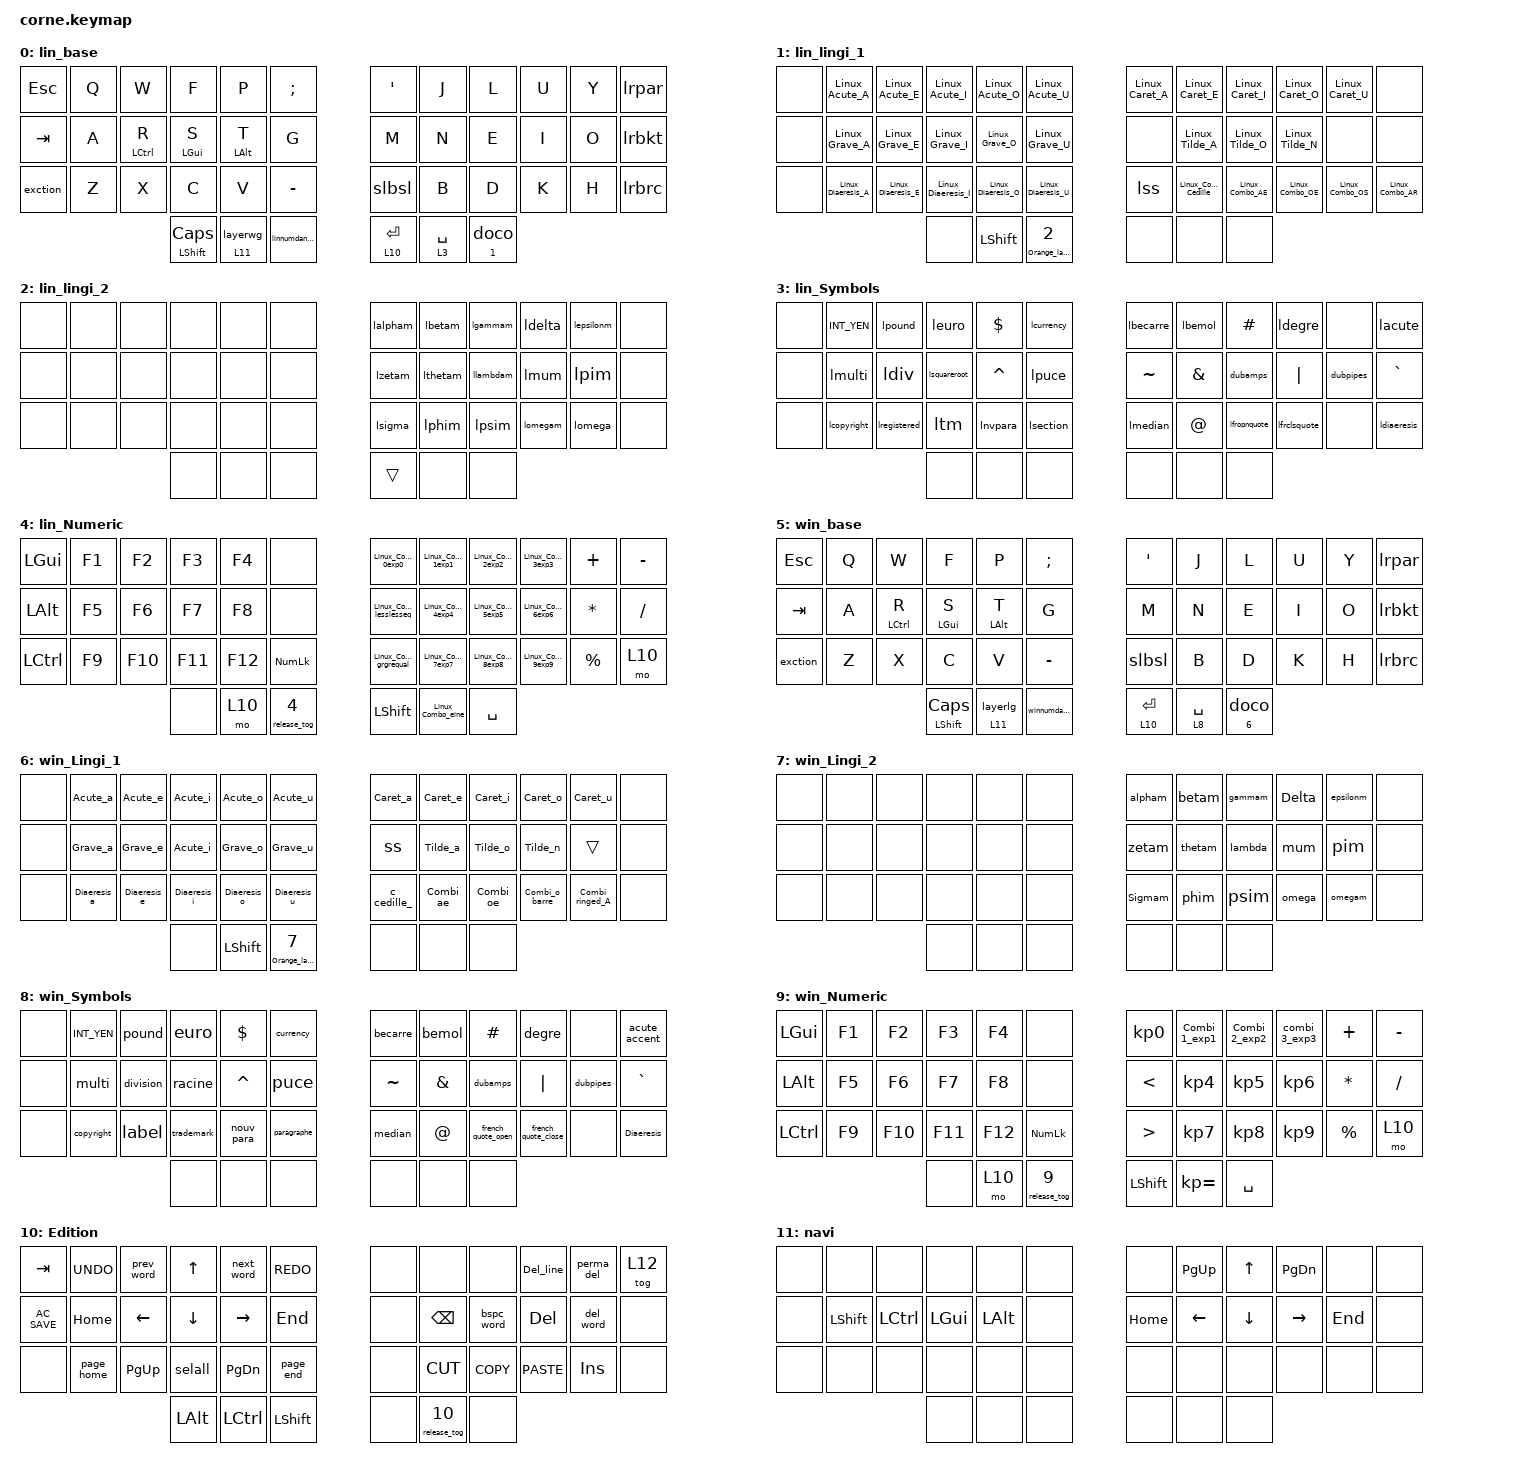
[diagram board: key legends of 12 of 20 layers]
#include <behaviors.dtsi>
#include <dt-bindings/zmk/bt.h>
#include <dt-bindings/zmk/keys.h>
#include <dt-bindings/zmk/rgb.h>

#define BASE 0
#define GAMING 1
#define LINGI 2
#define LINGI2 3
#define SYMBOLS 4
#define NUM 5
#define GAMINGNUM 6
#define EDITION 7
#define NAVI 8
#define APPLAUNCH 9
#define MEDIADISP 10
#define WINDOWMAN 11
#define CC 12
#define KC 13
#define LOCKED 14

#define MO_TOG(layer) &mo_tog layer layer

&sk { quick-release; };

/ {
    behaviors {
        exction: exction {
            compatible = "zmk,behavior-mod-morph";
            label = "EXCTION";
            bindings = <&kp EXCL>, <&kp QUESTION>;

            #binding-cells = <0>;
            mods = <(MOD_LSFT)>;
        };

        lrpar: lrpar {
            compatible = "zmk,behavior-mod-morph";
            label = "LRPAR";
            bindings = <&kp LPAR>, <&kp RPAR>;

            #binding-cells = <0>;
            mods = <(MOD_LSFT)>;
        };

        lrbkt: lrbkt {
            compatible = "zmk,behavior-mod-morph";
            label = "LRBKT";
            bindings = <&kp LBKT>, <&kp RBKT>;

            #binding-cells = <0>;
            mods = <(MOD_LSFT)>;
        };

        lrbrc: lrbrc {
            compatible = "zmk,behavior-mod-morph";
            label = "LRBRC";
            bindings = <&kp LBRC>, <&kp RBRC>;

            #binding-cells = <0>;
            mods = <(MOD_LSFT)>;
        };

        doco: doco {
            compatible = "zmk,behavior-mod-morph";
            label = "DOCO";
            bindings = <&kp DOT>, <&kp COMMA>;

            #binding-cells = <0>;
            mods = <(MOD_LSFT)>;
        };

        slbsl: slbsl {
            compatible = "zmk,behavior-mod-morph";
            label = "SLBSL";
            bindings = <&kp SLASH>, <&kp BACKSLASH>;

            #binding-cells = <0>;
            mods = <(MOD_LSFT)>;
        };

        homerow: homerow {
            compatible = "zmk,behavior-hold-tap";
            label = "HOMEROW";
            bindings = <&sk>, <&kp>;

            #binding-cells = <2>;
            hold-trigger-key-positions = <15 14 13>;
            tapping-term-ms = <200>;
            flavor = "tap-preferred";
        };

        htkp: htkp {
            compatible = "zmk,behavior-hold-tap";
            label = "HTKP";
            bindings = <&kp>, <&kp>;

            #binding-cells = <2>;
            tapping-term-ms = <200>;
        };

        orangelayer: orangelayer {
            compatible = "zmk,behavior-hold-tap";
            label = "ORANGELAYER";
            bindings = <&moorange>, <&doco>;

            #binding-cells = <2>;
            hold-trigger-key-positions = <39 40 41>;
            tapping-term-ms = <100>;
        };

        cyanlayer: cyanlayer {
            compatible = "zmk,behavior-hold-tap";
            label = "CYANLAYER";
            bindings = <&mocyan>, <&kp>;

            #binding-cells = <2>;
            hold-trigger-key-positions = <39 40 41>;
            tapping-term-ms = <100>;
        };

        c_cedille_: c_cedille_ {
            compatible = "zmk,behavior-mod-morph";
            label = "C_CEDILLE_";
            bindings = <&c_cedillem>, <&C_cedille>;

            #binding-cells = <0>;
            mods = <(MOD_LSFT)>;
        };

        Acute_a: Acute_a {
            compatible = "zmk,behavior-mod-morph";
            label = "ACUTE_A";
            bindings = <&aam>, <&Aa>;

            #binding-cells = <0>;
            mods = <(MOD_LSFT)>;
        };

        Acute_e: Acute_e {
            compatible = "zmk,behavior-mod-morph";
            label = "ACUTE_E";
            bindings = <&eam>, <&Ea>;

            #binding-cells = <0>;
            mods = <(MOD_LSFT)>;
        };

        Acute_i: Acute_i {
            compatible = "zmk,behavior-mod-morph";
            label = "ACUTE_I";
            bindings = <&iam>, <&Ia>;

            #binding-cells = <0>;
            mods = <(MOD_LSFT)>;
        };

        Acute_o: Acute_o {
            compatible = "zmk,behavior-mod-morph";
            label = "ACUTE_O";
            bindings = <&oam>, <&Oa>;

            #binding-cells = <0>;
            mods = <(MOD_LSFT)>;
        };

        Acute_u: Acute_u {
            compatible = "zmk,behavior-mod-morph";
            label = "ACUTE_U";
            bindings = <&uam>, <&Ua>;

            #binding-cells = <0>;
            mods = <(MOD_LSFT)>;
        };

        Grave_a: Grave_a {
            compatible = "zmk,behavior-mod-morph";
            label = "GRAVE_A";
            bindings = <&agm>, <&ag>;

            #binding-cells = <0>;
            mods = <(MOD_LSFT)>;
        };

        Grave_e: Grave_e {
            compatible = "zmk,behavior-mod-morph";
            label = "GRAVE_E";
            bindings = <&egm>, <&eg>;

            #binding-cells = <0>;
            mods = <(MOD_LSFT)>;
        };

        Grave_o: Grave_o {
            compatible = "zmk,behavior-mod-morph";
            label = "GRAVE_O";
            bindings = <&ogm>, <&og>;

            #binding-cells = <0>;
            mods = <(MOD_LSFT)>;
        };

        Grave_u: Grave_u {
            compatible = "zmk,behavior-mod-morph";
            label = "GRAVE_U";
            bindings = <&ugm>, <&ug>;

            #binding-cells = <0>;
            mods = <(MOD_LSFT)>;
        };

        Diaeresis_a: Diaeresis_a {
            compatible = "zmk,behavior-mod-morph";
            label = "DIAERESIS_A";
            bindings = <&adm>, <&ad>;

            #binding-cells = <0>;
            mods = <(MOD_LSFT)>;
        };

        Diaeresis_e: Diaeresis_e {
            compatible = "zmk,behavior-mod-morph";
            label = "DIAERESIS_E";
            bindings = <&edm>, <&ed>;

            #binding-cells = <0>;
            mods = <(MOD_LSFT)>;
        };

        Diaeresis_i: Diaeresis_i {
            compatible = "zmk,behavior-mod-morph";
            label = "DIAERESIS_I";
            bindings = <&idm>, <&id>;

            #binding-cells = <0>;
            mods = <(MOD_LSFT)>;
        };

        Diaeresis_o: Diaeresis_o {
            compatible = "zmk,behavior-mod-morph";
            label = "DIAERESIS_O";
            bindings = <&odm>, <&od>;

            #binding-cells = <0>;
            mods = <(MOD_LSFT)>;
        };

        Diaeresis_u: Diaeresis_u {
            compatible = "zmk,behavior-mod-morph";
            label = "DIAERESIS_U";
            bindings = <&udm>, <&ud>;

            #binding-cells = <0>;
            mods = <(MOD_LSFT)>;
        };

        Caret_a: Caret_a {
            compatible = "zmk,behavior-mod-morph";
            label = "CARET_A";
            bindings = <&acm>, <&ac>;

            #binding-cells = <0>;
            mods = <(MOD_LSFT)>;
        };

        Caret_e: Caret_e {
            compatible = "zmk,behavior-mod-morph";
            label = "CARET_E";
            bindings = <&ecm>, <&ec>;

            #binding-cells = <0>;
            mods = <(MOD_LSFT)>;
        };

        Caret_i: Caret_i {
            compatible = "zmk,behavior-mod-morph";
            label = "CARET_I";
            bindings = <&icm>, <&ic>;

            #binding-cells = <0>;
            mods = <(MOD_LSFT)>;
        };

        Caret_o: Caret_o {
            compatible = "zmk,behavior-mod-morph";
            label = "CARET_O";
            bindings = <&ocm>, <&oc>;

            #binding-cells = <0>;
            mods = <(MOD_LSFT)>;
        };

        Caret_u: Caret_u {
            compatible = "zmk,behavior-mod-morph";
            label = "CARET_U";
            bindings = <&ucm>, <&uc>;

            #binding-cells = <0>;
            mods = <(MOD_LSFT)>;
        };

        Tilde_a: Tilde_a {
            compatible = "zmk,behavior-mod-morph";
            label = "TILDE_A";
            bindings = <&atm>, <&at>;

            #binding-cells = <0>;
            mods = <(MOD_LSFT)>;
        };

        Tilde_o: Tilde_o {
            compatible = "zmk,behavior-mod-morph";
            label = "TILDE_O";
            bindings = <&otm>, <&ot>;

            #binding-cells = <0>;
            mods = <(MOD_LSFT)>;
        };

        Tilde_n: Tilde_n {
            compatible = "zmk,behavior-mod-morph";
            label = "TILDE_N";
            bindings = <&ntm>, <&nt>;

            #binding-cells = <0>;
            mods = <(MOD_LSFT)>;
        };

        Combi_ae: Combi_ae {
            compatible = "zmk,behavior-mod-morph";
            label = "COMBI_AE";
            bindings = <&aem>, <&AE>;

            #binding-cells = <0>;
            mods = <(MOD_LSFT)>;
        };

        Combi_oe: Combi_oe {
            compatible = "zmk,behavior-mod-morph";
            label = "COMBI_OE";
            bindings = <&oem>, <&OE>;

            #binding-cells = <0>;
            mods = <(MOD_LSFT)>;
        };

        Combi_o_barre: Combi_o_barre {
            compatible = "zmk,behavior-mod-morph";
            label = "COMBI_O_BARRE";
            bindings = <&o_barrem>, <&O_barre>;

            #binding-cells = <0>;
            mods = <(MOD_LSFT)>;
        };

        Combi_ringed_A: Combi_ringed_A {
            compatible = "zmk,behavior-mod-morph";
            label = "COMBI_RINGED_A";
            bindings = <&arm>, <&Ar>;

            #binding-cells = <0>;
            mods = <(MOD_LSFT)>;
        };

        Combi_1_exp1: Combi_1_exp1 {
            compatible = "zmk,behavior-mod-morph";
            label = "COMBI_1_EXP1";
            bindings = <&kp KP_N1>, <&exp1>;

            #binding-cells = <0>;
            mods = <(MOD_LSFT)>;
        };

        Combi_2_exp2: Combi_2_exp2 {
            compatible = "zmk,behavior-mod-morph";
            label = "COMBI_2_EXP2";
            bindings = <&kp KP_N2>, <&exp2>;

            #binding-cells = <0>;
            mods = <(MOD_LSFT)>;
        };

        combi_3_exp3: combi_3_exp3 {
            compatible = "zmk,behavior-mod-morph";
            label = "COMBI_3_EXP3";
            bindings = <&kp KP_N3>, <&exp3>;

            #binding-cells = <0>;
            mods = <(MOD_LSFT)>;
        };

        Linux_Acute_A: Linux_Acute_A {
            compatible = "zmk,behavior-mod-morph";
            label = "LINUX_ACUTE_A";
            bindings = <&laam>, <&laa>;

            #binding-cells = <0>;
            mods = <(MOD_LSFT)>;
        };

        Linux_Acute_E: Linux_Acute_E {
            compatible = "zmk,behavior-mod-morph";
            label = "LINUX_ACUTE_E";
            bindings = <&leam>, <&lea>;

            #binding-cells = <0>;
            mods = <(MOD_LSFT)>;
        };

        Linux_Acute_I: Linux_Acute_I {
            compatible = "zmk,behavior-mod-morph";
            label = "LINUX_ACUTE_I";
            bindings = <&liam>, <&lia>;

            #binding-cells = <0>;
            mods = <(MOD_LSFT)>;
        };

        Linux_Acute_O: Linux_Acute_O {
            compatible = "zmk,behavior-mod-morph";
            label = "LINUX_ACUTE_O";
            bindings = <&loam>, <&loa>;

            #binding-cells = <0>;
            mods = <(MOD_LSFT)>;
        };

        Linux_Acute_U: Linux_Acute_U {
            compatible = "zmk,behavior-mod-morph";
            label = "LINUX_ACUTE_U";
            bindings = <&luam>, <&lua>;

            #binding-cells = <0>;
            mods = <(MOD_LSFT)>;
        };

        Linux_Grave_A: Linux_Grave_A {
            compatible = "zmk,behavior-mod-morph";
            label = "LINUX_GRAVE_A";
            bindings = <&lagm>, <&lag>;

            #binding-cells = <0>;
            mods = <(MOD_LSFT)>;
        };

        Linux_Grave_E: Linux_Grave_E {
            compatible = "zmk,behavior-mod-morph";
            label = "LINUX_GRAVE_E";
            bindings = <&legm>, <&leg>;

            #binding-cells = <0>;
            mods = <(MOD_LSFT)>;
        };

        Linux_Grave_I: Linux_Grave_I {
            compatible = "zmk,behavior-mod-morph";
            label = "LINUX_GRAVE_I";
            bindings = <&ligm>, <&lig>;

            #binding-cells = <0>;
            mods = <(MOD_LSFT)>;
        };

        Linux_Grave_O: Linux_Grave_O {
            compatible = "zmk,behavior-mod-morph";
            label = "LINUX_GRAVE_O";
            bindings = <&logm>, <&log>;

            #binding-cells = <0>;
            mods = <(MOD_LSFT)>;
        };

        Linux_Grave_U: Linux_Grave_U {
            compatible = "zmk,behavior-mod-morph";
            label = "LINUX_GRAVE_U";
            bindings = <&lugm>, <&lug>;

            #binding-cells = <0>;
            mods = <(MOD_LSFT)>;
        };

        Linux_Diaeresis_A: Linux_Diaeresis_A {
            compatible = "zmk,behavior-mod-morph";
            label = "LINUX_DIAERESIS_A";
            bindings = <&ladm>, <&lad>;

            #binding-cells = <0>;
            mods = <(MOD_LSFT)>;
        };

        Linux_Diaeresis_E: Linux_Diaeresis_E {
            compatible = "zmk,behavior-mod-morph";
            label = "LINUX_DIAERESIS_E";
            bindings = <&ledm>, <&led>;

            #binding-cells = <0>;
            mods = <(MOD_LSFT)>;
        };

        Linux_Diaeresis_I: Linux_Diaeresis_I {
            compatible = "zmk,behavior-mod-morph";
            label = "LINUX_DIAERESIS_I";
            bindings = <&lidm>, <&lid>;

            #binding-cells = <0>;
            mods = <(MOD_LSFT)>;
        };

        Linux_Diaeresis_O: Linux_Diaeresis_O {
            compatible = "zmk,behavior-mod-morph";
            label = "LINUX_DIAERESIS_O";
            bindings = <&lodm>, <&lod>;

            #binding-cells = <0>;
            mods = <(MOD_LSFT)>;
        };

        Linux_Diaeresis_U: Linux_Diaeresis_U {
            compatible = "zmk,behavior-mod-morph";
            label = "LINUX_DIAERESIS_U";
            bindings = <&ludm>, <&lud>;

            #binding-cells = <0>;
            mods = <(MOD_LSFT)>;
        };

        Linux_Caret_A: Linux_Caret_A {
            compatible = "zmk,behavior-mod-morph";
            label = "LINUX_CARET_A";
            bindings = <&lacm>, <&lac>;

            #binding-cells = <0>;
            mods = <(MOD_LSFT)>;
        };

        Linux_Caret_E: Linux_Caret_E {
            compatible = "zmk,behavior-mod-morph";
            label = "LINUX_CARET_E";
            bindings = <&lecm>, <&lec>;

            #binding-cells = <0>;
            mods = <(MOD_LSFT)>;
        };

        Linux_Caret_I: Linux_Caret_I {
            compatible = "zmk,behavior-mod-morph";
            label = "LINUX_CARET_I";
            bindings = <&licm>, <&lic>;

            #binding-cells = <0>;
            mods = <(MOD_LSFT)>;
        };

        Linux_Caret_O: Linux_Caret_O {
            compatible = "zmk,behavior-mod-morph";
            label = "LINUX_CARET_O";
            bindings = <&locm>, <&loc>;

            #binding-cells = <0>;
            mods = <(MOD_LSFT)>;
        };

        Linux_Caret_U: Linux_Caret_U {
            compatible = "zmk,behavior-mod-morph";
            label = "LINUX_CARET_U";
            bindings = <&lucm>, <&luc>;

            #binding-cells = <0>;
            mods = <(MOD_LSFT)>;
        };

        Linux_Tilde_A: Linux_Tilde_A {
            compatible = "zmk,behavior-mod-morph";
            label = "LINUX_TILDE_A";
            bindings = <&latm>, <&lat>;

            #binding-cells = <0>;
            mods = <(MOD_LSFT)>;
        };

        Linux_Tilde_O: Linux_Tilde_O {
            compatible = "zmk,behavior-mod-morph";
            label = "LINUX_TILDE_O";
            bindings = <&lotm>, <&lot>;

            #binding-cells = <0>;
            mods = <(MOD_LSFT)>;
        };

        Linux_Tilde_N: Linux_Tilde_N {
            compatible = "zmk,behavior-mod-morph";
            label = "LINUX_TILDE_N";
            bindings = <&lntm>, <&lnt>;

            #binding-cells = <0>;
            mods = <(MOD_LSFT)>;
        };

        Linux_Combo_AE: Linux_Combo_AE {
            compatible = "zmk,behavior-mod-morph";
            label = "LINUX_COMBO_AE";
            bindings = <&laem>, <&lae>;

            #binding-cells = <0>;
            mods = <(MOD_LSFT)>;
        };

        Linux_Combo_OE: Linux_Combo_OE {
            compatible = "zmk,behavior-mod-morph";
            label = "LINUX_COMBO_OE";
            bindings = <&loem>, <&loe>;

            #binding-cells = <0>;
            mods = <(MOD_LSFT)>;
        };

        Linux_Combo_Cedille: Linux_Combo_Cedille {
            compatible = "zmk,behavior-mod-morph";
            label = "LINUX_COMBO_CEDILLE";
            bindings = <&lcedillem>, <&lcedille>;

            #binding-cells = <0>;
            mods = <(MOD_LSFT)>;
        };

        Linux_Combo_AR: Linux_Combo_AR {
            compatible = "zmk,behavior-mod-morph";
            label = "LINUX_COMBO_AR";
            bindings = <&larm>, <&lar>;

            #binding-cells = <0>;
            mods = <(MOD_LSFT)>;
        };

        Linux_Combo_OS: Linux_Combo_OS {
            compatible = "zmk,behavior-mod-morph";
            label = "LINUX_COMBO_OS";
            bindings = <&losm>, <&los>;

            #binding-cells = <0>;
            mods = <(MOD_LSFT)>;
        };

        Linux_Combo_0exp0: Linux_Combo_0exp0 {
            compatible = "zmk,behavior-mod-morph";
            label = "LINUX_COMBO_0EXP0";
            bindings = <&kp KP_N0>, <&lexp0>;

            #binding-cells = <0>;
            mods = <(MOD_LSFT)>;
        };

        Linux_Combo_1exp1: Linux_Combo_1exp1 {
            compatible = "zmk,behavior-mod-morph";
            label = "LINUX_COMBO_1EXP1";
            bindings = <&kp KP_NUMBER_1>, <&lexp1>;

            #binding-cells = <0>;
            mods = <(MOD_LSFT)>;
        };

        Linux_Combo_2exp2: Linux_Combo_2exp2 {
            compatible = "zmk,behavior-mod-morph";
            label = "LINUX_COMBO_2EXP2";
            bindings = <&kp KP_NUMBER_2>, <&lexp2>;

            #binding-cells = <0>;
            mods = <(MOD_LSFT)>;
        };

        Linux_Combo_3exp3: Linux_Combo_3exp3 {
            compatible = "zmk,behavior-mod-morph";
            label = "LINUX_COMBO_3EXP3";
            bindings = <&kp KP_NUMBER_3>, <&lexp3>;

            #binding-cells = <0>;
            mods = <(MOD_LSFT)>;
        };

        Linux_Combo_4exp4: Linux_Combo_4exp4 {
            compatible = "zmk,behavior-mod-morph";
            label = "LINUX_COMBO_4EXP4";
            bindings = <&kp KP_NUMBER_4>, <&lexp4>;

            #binding-cells = <0>;
            mods = <(MOD_LSFT)>;
        };

        Linux_Combo_5exp5: Linux_Combo_5exp5 {
            compatible = "zmk,behavior-mod-morph";
            label = "LINUX_COMBO_5EXP5";
            bindings = <&kp KP_NUMBER_5>, <&lexp5>;

            #binding-cells = <0>;
            mods = <(MOD_LSFT)>;
        };

        Linux_Combo_6exp6: Linux_Combo_6exp6 {
            compatible = "zmk,behavior-mod-morph";
            label = "LINUX_COMBO_6EXP6";
            bindings = <&kp KP_NUMBER_6>, <&lexp6>;

            #binding-cells = <0>;
            mods = <(MOD_LSFT)>;
        };

        Linux_Combo_7exp7: Linux_Combo_7exp7 {
            compatible = "zmk,behavior-mod-morph";
            label = "LINUX_COMBO_7EXP7";
            bindings = <&kp N7>, <&lexp7>;

            #binding-cells = <0>;
            mods = <(MOD_LSFT)>;
        };

        Linux_Combo_8exp8: Linux_Combo_8exp8 {
            compatible = "zmk,behavior-mod-morph";
            label = "LINUX_COMBO_8EXP8";
            bindings = <&kp N8>, <&lexp8>;

            #binding-cells = <0>;
            mods = <(MOD_LSFT)>;
        };

        Linux_Combo_9exp9: Linux_Combo_9exp9 {
            compatible = "zmk,behavior-mod-morph";
            label = "LINUX_COMBO_9EXP9";
            bindings = <&kp N9>, <&lexp9>;

            #binding-cells = <0>;
            mods = <(MOD_LSFT)>;
        };

        Linux_Combo_lesslesseq: Linux_Combo_lesslesseq {
            compatible = "zmk,behavior-mod-morph";
            label = "LINUX_COMBO_LESSLESSEQ";
            bindings = <&kp LESS_THAN>, <&llessequal>;

            #binding-cells = <0>;
            mods = <(MOD_LSFT)>;
        };

        Linux_Combo_grgrequal: Linux_Combo_grgrequal {
            compatible = "zmk,behavior-mod-morph";
            label = "LINUX_COMBO_GRGREQUAL";
            bindings = <&kp GREATER_THAN>, <&lgreaterequal>;

            #binding-cells = <0>;
            mods = <(MOD_LSFT)>;
        };

        Linux_Combo_eine: Linux_Combo_eine {
            compatible = "zmk,behavior-mod-morph";
            label = "LINUX_COMBO_EINE";
            bindings = <&kp EQUAL>, <&linequal>;

            #binding-cells = <0>;
            mods = <(MOD_LSFT)>;
        };

        layerwg: layerwg {
            compatible = "zmk,behavior-mod-morph";
            label = "LAYERWG";
            bindings = <&to 5>, <&tog 13>;

            #binding-cells = <0>;
            mods = <(MOD_LCTL)>;
        };

        mo_kp: mo_kp {
            compatible = "zmk,behavior-hold-tap";
            label = "MO_KP";
            bindings = <&mo>, <&kp>;

            #binding-cells = <2>;
            hold-trigger-key-positions = <39 40 41 38 37>;
            tapping-term-ms = <130>;
        };

        layerlg: layerlg {
            compatible = "zmk,behavior-mod-morph";
            label = "LAYERLG";
            bindings = <&to 0>, <&tog 13>;

            #binding-cells = <0>;
            mods = <(MOD_LCTL)>;
        };

        wgnavi: wgnavi {
            compatible = "zmk,behavior-hold-tap";
            label = "WGNAVI";
            bindings = <&mo>, <&layerwg>;

            #binding-cells = <2>;
            hold-trigger-key-positions = <39 40 41 38 37>;
            tapping-term-ms = <130>;
        };

        lgnavi: lgnavi {
            compatible = "zmk,behavior-hold-tap";
            label = "LGNAVI";
            bindings = <&mo>, <&layerlg>;

            #binding-cells = <2>;
            hold-trigger-key-positions = <39 40 41 38 37>;
            tapping-term-ms = <130>;
        };

        linnumdance: linnumdance {
            compatible = "zmk,behavior-tap-dance";
            label = "LINNUMDANCE";
            #binding-cells = <0>;
            bindings = <&mo 4>, <&tog 4>;
        };

        winnumdance: winnumdance {
            compatible = "zmk,behavior-tap-dance";
            label = "WINNUMDANCE";
            #binding-cells = <0>;
            bindings = <&mo 9>, <&tog 9>;
        };
    };

    macros {
        mogreen: morgb {
            compatible = "zmk,behavior-macro-one-param";
            #binding-cells = <1>;
            bindings =
                <&macro_param_1to1>,
                <&macro_press>,
                <&mo MACRO_PLACEHOLDER>,
                <&macro_tap>,
                <&rgb_ug RGB_COLOR_HSB(123,100,49)>,
                <&macro_pause_for_release>,
                <&macro_param_1to1>,
                <&macro_release>,
                <&mo MACRO_PLACEHOLDER>,
                <&macro_tap>,
                <&rgb_ug RGB_COLOR_HSB(301,100,48)>;

            label = "MORGB";
        };

        moorange: moorange {
            compatible = "zmk,behavior-macro-one-param";
            #binding-cells = <1>;
            bindings =
                <&macro_param_1to1>,
                <&macro_press>,
                <&mo MACRO_PLACEHOLDER>,
                <&macro_tap>,
                <&rgb_ug RGB_COLOR_HSB(24,100,49)>,
                <&macro_press>,
                <&macro_pause_for_release>,
                <&macro_release>,
                <&macro_param_1to1 &mo MACRO_PLACEHOLDER>,
                <&macro_tap>,
                <&rgb_ug RGB_COLOR_HSB(301,100,48)>;

            label = "MOORANGE";
        };

        mocyan: mocyan {
            compatible = "zmk,behavior-macro-one-param";
            #binding-cells = <1>;
            bindings =
                <&macro_param_1to1>,
                <&macro_press>,
                <&mo MACRO_PLACEHOLDER>,
                <&macro_tap>,
                <&rgb_ug RGB_COLOR_HSB(180,100,49)>,
                <&macro_pause_for_release>,
                <&macro_release>,
                <&macro_param_1to1 &mo MACRO_PLACEHOLDER>,
                <&macro_tap>,
                <&rgb_ug RGB_COLOR_HSB(301,100,48)>;

            label = "MOCYAN";
        };

        release_tog: release_tog {
            compatible = "zmk,behavior-macro-one-param";
            #binding-cells = <1>;
            bindings =
                <&macro_param_1to1>,
                <&macro_tap>,
                <&tog MACRO_PLACEHOLDER>,
                <&macro_tap>,
                <&rgb_ug RGB_COLOR_HSB(301,100,48)>;

            label = "RELEASE_TOG";
        };

        tog_purple: tog_purple {
            compatible = "zmk,behavior-macro-one-param";
            #binding-cells = <1>;
            bindings =
                <&macro_tap>,
                <&rgb_ug RGB_COLOR_HSB(267,100,49) &macro_param_1to1>,
                <&macro_tap>,
                <&tog MACRO_PLACEHOLDER>;

            label = "TOG_PURPLE";
        };

        tog_yellow: tog_yellow {
            compatible = "zmk,behavior-macro-one-param";
            #binding-cells = <1>;
            bindings =
                <&macro_tap>,
                <&rgb_ug RGB_COLOR_HSB(56,100,49) &macro_param_1to1>,
                <&macro_tap>,
                <&tog MACRO_PLACEHOLDER>;

            label = "TOG_YELLOW";
        };

        mopurple: mopurple {
            compatible = "zmk,behavior-macro-one-param";
            #binding-cells = <1>;
            bindings =
                <&macro_param_1to1>,
                <&macro_press>,
                <&mo MACRO_PLACEHOLDER>,
                <&macro_tap>,
                <&rgb_ug RGB_COLOR_HSB(267,100,49)>,
                <&macro_pause_for_release>,
                <&macro_param_1to1>,
                <&macro_release>,
                <&kp MACRO_PLACEHOLDER>,
                <&macro_tap>,
                <&rgb_ug RGB_COLOR_HSB(304,100,50)>;

            label = "MOPURPLE";
        };

        moyellow: yellow {
            compatible = "zmk,behavior-macro-one-param";
            #binding-cells = <1>;
            bindings =
                <&macro_param_1to1>,
                <&macro_press>,
                <&mo MACRO_PLACEHOLDER>,
                <&macro_tap>,
                <&rgb_ug RGB_COLOR_HSB(63,100,49)>,
                <&macro_pause_for_release>,
                <&macro_param_1to1>,
                <&macro_release>,
                <&mo MACRO_PLACEHOLDER>,
                <&macro_tap>,
                <&rgb_ug RGB_COLOR_HSB(304,100,50)>;

            label = "YELLOW";
        };

        aem: aem {
            compatible = "zmk,behavior-macro";
            #binding-cells = <0>;
            bindings =
                <&macro_press>,
                <&kp LALT>,
                <&macro_tap>,
                <&kp KP_NUMBER_0 &kp KP_NUMBER_2 &kp KP_NUMBER_3 &kp KP_NUMBER_0>,
                <&macro_release>,
                <&kp LALT>;

            label = "AEM";
        };

        AE: AE {
            compatible = "zmk,behavior-macro";
            #binding-cells = <0>;
            bindings =
                <&macro_press>,
                <&kp LALT>,
                <&macro_tap>,
                <&kp KP_NUMBER_0 &kp KP_NUMBER_1 &kp KP_NUMBER_9 &kp KP_NUMBER_8>,
                <&macro_release>,
                <&kp LALT>;

            label = "AE";
        };

        c_cedillem: c_cedillem {
            compatible = "zmk,behavior-macro";
            #binding-cells = <0>;
            bindings =
                <&macro_press>,
                <&kp LALT>,
                <&macro_tap>,
                <&kp KP_NUMBER_0 &kp KP_NUMBER_2 &kp KP_NUMBER_3 &kp KP_NUMBER_1>,
                <&macro_release>,
                <&kp LALT>;

            label = "C_CEDILLEM";
        };

        C_cedille: C_cedille {
            compatible = "zmk,behavior-macro";
            #binding-cells = <0>;
            bindings =
                <&macro_press>,
                <&kp LALT>,
                <&macro_tap>,
                <&kp KP_NUMBER_0 &kp KP_NUMBER_1 &kp KP_NUMBER_9 &kp KP_NUMBER_9>,
                <&macro_release>,
                <&kp LALT>;

            label = "C_CEDILLE";
        };

        o_barrem: o_barrem {
            compatible = "zmk,behavior-macro";
            #binding-cells = <0>;
            bindings =
                <&macro_press>,
                <&kp LALT>,
                <&macro_tap>,
                <&kp KP_NUMBER_0 &kp KP_NUMBER_2 &kp KP_NUMBER_4 &kp KP_NUMBER_8>,
                <&macro_release>,
                <&kp LALT>;

            label = "O_BARREM";
        };

        O_barre: O_barre {
            compatible = "zmk,behavior-macro";
            #binding-cells = <0>;
            bindings =
                <&macro_press>,
                <&kp LALT>,
                <&macro_tap>,
                <&kp KP_NUMBER_0 &kp KP_NUMBER_2 &kp KP_NUMBER_1 &kp KP_NUMBER_6>,
                <&macro_release>,
                <&kp LALT>;

            label = "O_BARRE";
        };

        ss: ss {
            compatible = "zmk,behavior-macro";
            #binding-cells = <0>;
            bindings =
                <&macro_press>,
                <&kp LALT>,
                <&macro_tap>,
                <&kp KP_NUMBER_0 &kp KP_NUMBER_2 &kp KP_NUMBER_2 &kp KP_NUMBER_3>,
                <&macro_release>,
                <&kp LALT>;

            label = "SS";
        };

        oem: oem {
            compatible = "zmk,behavior-macro";
            #binding-cells = <0>;
            bindings =
                <&macro_press>,
                <&kp LALT>,
                <&macro_tap>,
                <&kp KP_NUMBER_0 &kp KP_NUMBER_1 &kp KP_NUMBER_5 &kp KP_NUMBER_6>,
                <&macro_release>,
                <&kp LALT>;

            label = "OEM";
        };

        OE: OE {
            compatible = "zmk,behavior-macro";
            #binding-cells = <0>;
            bindings =
                <&macro_press>,
                <&kp LALT>,
                <&macro_tap>,
                <&kp KP_NUMBER_0 &kp KP_NUMBER_1 &kp KP_NUMBER_4 &kp KP_NUMBER_0>,
                <&macro_release>,
                <&kp LALT>;

            label = "OE";
        };

        arm: arm {
            compatible = "zmk,behavior-macro";
            #binding-cells = <0>;
            bindings =
                <&macro_press>,
                <&kp LALT>,
                <&macro_tap>,
                <&kp KP_NUMBER_0 &kp KP_NUMBER_2 &kp KP_NUMBER_2 &kp KP_NUMBER_9>,
                <&macro_release>,
                <&kp LALT>;

            label = "ARM";
        };

        Ar: Ar {
            compatible = "zmk,behavior-macro";
            #binding-cells = <0>;
            bindings =
                <&macro_press>,
                <&kp LALT>,
                <&macro_tap>,
                <&kp KP_NUMBER_0 &kp KP_NUMBER_1 &kp KP_NUMBER_9 &kp KP_NUMBER_7>,
                <&macro_release>,
                <&kp LALT>;

            label = "AR";
        };

        Aa: aa {
            compatible = "zmk,behavior-macro";
            #binding-cells = <0>;
            bindings =
                <&macro_press>,
                <&kp LALT>,
                <&macro_tap>,
                <&kp KP_NUMBER_0 &kp KP_NUMBER_1 &kp KP_NUMBER_9 &kp KP_NUMBER_3>,
                <&macro_release>,
                <&kp LALT>;

            label = "AA";
        };

        aam: aam {
            compatible = "zmk,behavior-macro";
            #binding-cells = <0>;
            bindings =
                <&macro_press>,
                <&kp LALT>,
                <&macro_tap>,
                <&kp KP_NUMBER_0 &kp KP_NUMBER_2 &kp KP_NUMBER_2 &kp KP_NUMBER_5>,
                <&macro_release>,
                <&kp LALT>;

            label = "AAM";
        };

        Ea: Ea {
            compatible = "zmk,behavior-macro";
            #binding-cells = <0>;
            bindings =
                <&macro_press>,
                <&kp LALT>,
                <&macro_tap>,
                <&kp KP_NUMBER_0 &kp KP_NUMBER_2 &kp KP_NUMBER_0 &kp KP_NUMBER_1>,
                <&macro_release>,
                <&kp LALT>;

            label = "EA";
        };

        eam: eam {
            compatible = "zmk,behavior-macro";
            #binding-cells = <0>;
            bindings =
                <&macro_press>,
                <&kp LALT>,
                <&macro_tap>,
                <&kp KP_NUMBER_0 &kp KP_NUMBER_2 &kp KP_NUMBER_3 &kp KP_NUMBER_3>,
                <&macro_release>,
                <&kp LALT>;

            label = "EAM";
        };

        Ia: Ia {
            compatible = "zmk,behavior-macro";
            #binding-cells = <0>;
            bindings =
                <&macro_press>,
                <&kp LALT>,
                <&macro_tap>,
                <&kp KP_NUMBER_0 &kp KP_NUMBER_2 &kp KP_NUMBER_0 &kp KP_NUMBER_5>,
                <&macro_release>,
                <&kp LALT>;

            label = "IA";
        };

        iam: iam {
            compatible = "zmk,behavior-macro";
            #binding-cells = <0>;
            bindings =
                <&macro_press>,
                <&kp LALT>,
                <&macro_tap>,
                <&kp KP_NUMBER_0 &kp KP_NUMBER_2 &kp KP_NUMBER_3 &kp KP_NUMBER_7>,
                <&macro_release>,
                <&kp LALT>;

            label = "IAM";
        };

        Oa: Oa {
            compatible = "zmk,behavior-macro";
            #binding-cells = <0>;
            bindings =
                <&macro_press>,
                <&kp LALT>,
                <&macro_tap>,
                <&kp KP_NUMBER_0 &kp KP_NUMBER_2 &kp KP_NUMBER_1 &kp KP_NUMBER_1>,
                <&macro_release>,
                <&kp LALT>;

            label = "OA";
        };

        oam: oam {
            compatible = "zmk,behavior-macro";
            #binding-cells = <0>;
            bindings =
                <&macro_press>,
                <&kp LALT>,
                <&macro_tap>,
                <&kp KP_NUMBER_0 &kp KP_NUMBER_2 &kp KP_NUMBER_4 &kp KP_NUMBER_3>,
                <&macro_release>,
                <&kp LALT>;

            label = "OAM";
        };

        Ua: Ua {
            compatible = "zmk,behavior-macro";
            #binding-cells = <0>;
            bindings =
                <&macro_press>,
                <&kp LALT>,
                <&macro_tap>,
                <&kp KP_NUMBER_0 &kp KP_NUMBER_2 &kp KP_NUMBER_1 &kp KP_NUMBER_8>,
                <&macro_release>,
                <&kp LALT>;

            label = "UA";
        };

        uam: uam {
            compatible = "zmk,behavior-macro";
            #binding-cells = <0>;
            bindings =
                <&macro_press>,
                <&kp LALT>,
                <&macro_tap>,
                <&kp KP_NUMBER_0 &kp KP_NUMBER_2 &kp KP_NUMBER_5 &kp KP_NUMBER_0>,
                <&macro_release>,
                <&kp LALT>;

            label = "UAM";
        };

        ag: ag {
            compatible = "zmk,behavior-macro";
            #binding-cells = <0>;
            bindings =
                <&macro_press>,
                <&kp LALT>,
                <&macro_tap>,
                <&kp KP_NUMBER_0 &kp KP_NUMBER_1 &kp KP_NUMBER_9 &kp KP_NUMBER_2>,
                <&macro_release>,
                <&kp LALT>;

            label = "AG";
        };

        agm: agm {
            compatible = "zmk,behavior-macro";
            #binding-cells = <0>;
            bindings =
                <&macro_press>,
                <&kp LALT>,
                <&macro_tap>,
                <&kp KP_NUMBER_0 &kp KP_NUMBER_2 &kp KP_NUMBER_2 &kp KP_NUMBER_4>,
                <&macro_release>,
                <&kp LALT>;

            label = "AGM";
        };

        eg: eg {
            compatible = "zmk,behavior-macro";
            #binding-cells = <0>;
            bindings =
                <&macro_press>,
                <&kp LALT>,
                <&macro_tap>,
                <&kp KP_NUMBER_0 &kp KP_NUMBER_2 &kp KP_NUMBER_0 &kp KP_NUMBER_0>,
                <&macro_release>,
                <&kp LALT>;

            label = "EG";
        };

        egm: egm {
            compatible = "zmk,behavior-macro";
            #binding-cells = <0>;
            bindings =
                <&macro_press>,
                <&kp LALT>,
                <&macro_tap>,
                <&kp KP_NUMBER_0 &kp KP_NUMBER_2 &kp KP_NUMBER_3 &kp KP_N2>,
                <&macro_release>,
                <&kp LALT>;

            label = "EGM";
        };

        ug: ug {
            compatible = "zmk,behavior-macro";
            #binding-cells = <0>;
            bindings =
                <&macro_press>,
                <&kp LALT>,
                <&macro_tap>,
                <&kp KP_NUMBER_0 &kp KP_NUMBER_2 &kp KP_NUMBER_1 &kp KP_NUMBER_7>,
                <&macro_release>,
                <&kp LALT>;

            label = "UG";
        };

        ugm: ugm {
            compatible = "zmk,behavior-macro";
            #binding-cells = <0>;
            bindings =
                <&macro_press>,
                <&kp LALT>,
                <&macro_tap>,
                <&kp KP_NUMBER_0 &kp KP_NUMBER_2 &kp KP_NUMBER_4 &kp KP_NUMBER_9>,
                <&macro_release>,
                <&kp LALT>;

            label = "UGM";
        };

        og: og {
            compatible = "zmk,behavior-macro";
            #binding-cells = <0>;
            bindings =
                <&macro_press>,
                <&kp LALT>,
                <&macro_tap>,
                <&kp KP_NUMBER_0 &kp KP_NUMBER_2 &kp KP_NUMBER_1 &kp KP_NUMBER_0>,
                <&macro_release>,
                <&kp LALT>;

            label = "OG";
        };

        ogm: ogm {
            compatible = "zmk,behavior-macro";
            #binding-cells = <0>;
            bindings =
                <&macro_press>,
                <&kp LALT>,
                <&macro_tap>,
                <&kp KP_NUMBER_0 &kp KP_NUMBER_2 &kp KP_NUMBER_4 &kp KP_NUMBER_2>,
                <&macro_release>,
                <&kp LALT>;

            label = "OGM";
        };

        adm: adm {
            compatible = "zmk,behavior-macro";
            #binding-cells = <0>;
            bindings =
                <&macro_press>,
                <&kp LALT>,
                <&macro_tap>,
                <&kp KP_NUMBER_0 &kp KP_NUMBER_2 &kp KP_NUMBER_2 &kp KP_NUMBER_8>,
                <&macro_release>,
                <&kp LALT>;

            label = "ADM";
        };

        edm: edm {
            compatible = "zmk,behavior-macro";
            #binding-cells = <0>;
            bindings =
                <&macro_press>,
                <&kp LALT>,
                <&macro_tap>,
                <&kp KP_NUMBER_0 &kp KP_NUMBER_2 &kp KP_NUMBER_3 &kp KP_NUMBER_5>,
                <&macro_release>,
                <&kp LALT>;

            label = "EDM";
        };

        idm: idm {
            compatible = "zmk,behavior-macro";
            #binding-cells = <0>;
            bindings =
                <&macro_press>,
                <&kp LALT>,
                <&macro_tap>,
                <&kp KP_NUMBER_0 &kp KP_NUMBER_2 &kp KP_NUMBER_3 &kp KP_NUMBER_9>,
                <&macro_release>,
                <&kp LALT>;

            label = "IDM";
        };

        odm: odm {
            compatible = "zmk,behavior-macro";
            #binding-cells = <0>;
            bindings =
                <&macro_press>,
                <&kp LALT>,
                <&macro_tap>,
                <&kp KP_NUMBER_0 &kp KP_NUMBER_2 &kp KP_NUMBER_4 &kp KP_NUMBER_6>,
                <&macro_release>,
                <&kp LALT>;

            label = "ODM";
        };

        udm: udm {
            compatible = "zmk,behavior-macro";
            #binding-cells = <0>;
            bindings =
                <&macro_press>,
                <&kp LALT>,
                <&macro_tap>,
                <&kp KP_NUMBER_0 &kp KP_NUMBER_2 &kp KP_NUMBER_5 &kp KP_NUMBER_2>,
                <&macro_release>,
                <&kp LALT>;

            label = "UDM";
        };

        ad: ad {
            compatible = "zmk,behavior-macro";
            #binding-cells = <0>;
            bindings =
                <&macro_press>,
                <&kp LALT>,
                <&macro_tap>,
                <&kp KP_NUMBER_0 &kp KP_NUMBER_1 &kp KP_NUMBER_9 &kp KP_NUMBER_6>,
                <&macro_release>,
                <&kp LALT>;

            label = "AD";
        };

        ed: ed {
            compatible = "zmk,behavior-macro";
            #binding-cells = <0>;
            bindings =
                <&macro_press>,
                <&kp LALT>,
                <&macro_tap>,
                <&kp KP_NUMBER_0 &kp KP_NUMBER_2 &kp KP_NUMBER_0 &kp KP_NUMBER_3>,
                <&macro_release>,
                <&kp LALT>;

            label = "ED";
        };

        id: id {
            compatible = "zmk,behavior-macro";
            #binding-cells = <0>;
            bindings =
                <&macro_press>,
                <&kp LALT>,
                <&macro_tap>,
                <&kp KP_NUMBER_0 &kp KP_NUMBER_2 &kp KP_NUMBER_0 &kp KP_NUMBER_7>,
                <&macro_release>,
                <&kp LALT>;

            label = "ID";
        };

        od: od {
            compatible = "zmk,behavior-macro";
            #binding-cells = <0>;
            bindings =
                <&macro_press>,
                <&kp LALT>,
                <&macro_tap>,
                <&kp KP_NUMBER_0 &kp KP_NUMBER_2 &kp KP_NUMBER_1 &kp KP_NUMBER_4>,
                <&macro_release>,
                <&kp LALT>;

            label = "OD";
        };

        ud: ud {
            compatible = "zmk,behavior-macro";
            #binding-cells = <0>;
            bindings =
                <&macro_press>,
                <&kp LALT>,
                <&macro_tap>,
                <&kp KP_NUMBER_0 &kp KP_NUMBER_2 &kp KP_NUMBER_2 &kp KP_NUMBER_0>,
                <&macro_release>,
                <&kp LALT>;

            label = "UD";
        };

        ac: ac {
            compatible = "zmk,behavior-macro";
            #binding-cells = <0>;
            bindings =
                <&macro_press>,
                <&kp LALT>,
                <&macro_tap>,
                <&kp KP_NUMBER_0 &kp KP_NUMBER_1 &kp KP_NUMBER_9 &kp KP_NUMBER_4>,
                <&macro_release>,
                <&kp LALT>;

            label = "AC";
        };

        ec: ec {
            compatible = "zmk,behavior-macro";
            #binding-cells = <0>;
            bindings =
                <&macro_press>,
                <&kp LALT>,
                <&macro_tap>,
                <&kp KP_NUMBER_0 &kp KP_NUMBER_2 &kp KP_NUMBER_0 &kp KP_NUMBER_2>,
                <&macro_release>,
                <&kp LALT>;

            label = "EC";
        };

        ic: ic {
            compatible = "zmk,behavior-macro";
            #binding-cells = <0>;
            bindings =
                <&macro_press>,
                <&kp LALT>,
                <&macro_tap>,
                <&kp KP_NUMBER_0 &kp KP_NUMBER_2 &kp KP_NUMBER_0 &kp KP_NUMBER_6>,
                <&macro_release>,
                <&kp LALT>;

            label = "IC";
        };

        oc: oc {
            compatible = "zmk,behavior-macro";
            #binding-cells = <0>;
            bindings =
                <&macro_press>,
                <&kp LALT>,
                <&macro_tap>,
                <&kp KP_NUMBER_0 &kp KP_NUMBER_2 &kp KP_NUMBER_1 &kp KP_NUMBER_2>,
                <&macro_release>,
                <&kp LALT>;

            label = "OC";
        };

        uc: uc {
            compatible = "zmk,behavior-macro";
            #binding-cells = <0>;
            bindings =
                <&macro_press>,
                <&kp LALT>,
                <&macro_tap>,
                <&kp KP_NUMBER_0 &kp KP_NUMBER_2 &kp KP_NUMBER_1 &kp KP_NUMBER_9>,
                <&macro_release>,
                <&kp LALT>;

            label = "UC";
        };

        acm: acm {
            compatible = "zmk,behavior-macro";
            #binding-cells = <0>;
            bindings =
                <&macro_press>,
                <&kp LALT>,
                <&macro_tap>,
                <&kp KP_NUMBER_0 &kp KP_NUMBER_2 &kp KP_NUMBER_2 &kp KP_NUMBER_6>,
                <&macro_release>,
                <&kp LALT>;

            label = "ACM";
        };

        ecm: ecm {
            compatible = "zmk,behavior-macro";
            #binding-cells = <0>;
            bindings =
                <&macro_press>,
                <&kp LALT>,
                <&macro_tap>,
                <&kp KP_NUMBER_0 &kp KP_NUMBER_2 &kp KP_NUMBER_3 &kp KP_NUMBER_4>,
                <&macro_release>,
                <&kp LALT>;

            label = "ECM";
        };

        icm: icm {
            compatible = "zmk,behavior-macro";
            #binding-cells = <0>;
            bindings =
                <&macro_press>,
                <&kp LALT>,
                <&macro_tap>,
                <&kp KP_NUMBER_0 &kp KP_NUMBER_2 &kp KP_NUMBER_3 &kp KP_NUMBER_8>,
                <&macro_release>,
                <&kp LALT>;

            label = "ICM";
        };

        ocm: ocm {
            compatible = "zmk,behavior-macro";
            #binding-cells = <0>;
            bindings =
                <&macro_press>,
                <&kp LALT>,
                <&macro_tap>,
                <&kp KP_NUMBER_0 &kp KP_NUMBER_2 &kp KP_NUMBER_4 &kp KP_NUMBER_4>,
                <&macro_release>,
                <&kp LALT>;

            label = "OCM";
        };

        ucm: ucm {
            compatible = "zmk,behavior-macro";
            #binding-cells = <0>;
            bindings =
                <&macro_press>,
                <&kp LALT>,
                <&macro_tap>,
                <&kp KP_NUMBER_0 &kp KP_NUMBER_2 &kp KP_NUMBER_5 &kp KP_NUMBER_1>,
                <&macro_release>,
                <&kp LALT>;

            label = "UCM";
        };

        ntm: ntm {
            compatible = "zmk,behavior-macro";
            #binding-cells = <0>;
            bindings =
                <&macro_press>,
                <&kp LALT>,
                <&macro_tap>,
                <&kp KP_NUMBER_0 &kp KP_NUMBER_2 &kp KP_NUMBER_4 &kp KP_NUMBER_1>,
                <&macro_release>,
                <&kp LALT>;

            label = "NTM";
        };

        nt: nt {
            compatible = "zmk,behavior-macro";
            #binding-cells = <0>;
            bindings =
                <&macro_press>,
                <&kp LALT>,
                <&macro_tap>,
                <&kp KP_NUMBER_0 &kp KP_NUMBER_2 &kp KP_NUMBER_0 &kp KP_NUMBER_9>,
                <&macro_release>,
                <&kp LALT>;

            label = "NT";
        };

        atm: atm {
            compatible = "zmk,behavior-macro";
            #binding-cells = <0>;
            bindings =
                <&macro_press>,
                <&kp LALT>,
                <&macro_tap>,
                <&kp KP_NUMBER_0 &kp KP_NUMBER_2 &kp KP_NUMBER_2 &kp KP_NUMBER_7>,
                <&macro_release>,
                <&kp LALT>;

            label = "ATM";
        };

        at: at {
            compatible = "zmk,behavior-macro";
            #binding-cells = <0>;
            bindings =
                <&macro_press>,
                <&kp LALT>,
                <&macro_tap>,
                <&kp KP_NUMBER_0 &kp KP_NUMBER_1 &kp KP_NUMBER_9 &kp KP_NUMBER_5>,
                <&macro_release>,
                <&kp LALT>;

            label = "AT";
        };

        otm: otm {
            compatible = "zmk,behavior-macro";
            #binding-cells = <0>;
            bindings =
                <&macro_press>,
                <&kp LALT>,
                <&macro_tap>,
                <&kp KP_NUMBER_0 &kp KP_NUMBER_2 &kp KP_NUMBER_4 &kp KP_NUMBER_5>,
                <&macro_release>,
                <&kp LALT>;

            label = "OTM";
        };

        ot: ot {
            compatible = "zmk,behavior-macro";
            #binding-cells = <0>;
            bindings =
                <&macro_press>,
                <&kp LALT>,
                <&macro_tap>,
                <&kp KP_NUMBER_0 &kp KP_NUMBER_2 &kp KP_NUMBER_1 &kp KP_NUMBER_3>,
                <&macro_release>,
                <&kp LALT>;

            label = "OT";
        };

        Orange_layer_2: Orange_layer_2 {
            compatible = "zmk,behavior-macro-one-param";
            #binding-cells = <1>;
            bindings =
                <&macro_param_1to1>,
                <&macro_press>,
                <&mo MACRO_PLACEHOLDER>,
                <&macro_press>,
                <&rgb_ug RGB_COLOR_HSB(38,100,70)>,
                <&macro_press>,
                <&macro_pause_for_release>,
                <&macro_release>,
                <&macro_param_1to1 &mo MACRO_PLACEHOLDER>,
                <&macro_tap>,
                <&rgb_ug RGB_COLOR_HSB(301,100,48)>;

            label = "ORANGE_LAYER_2";
        };

        alpham: alpha {
            compatible = "zmk,behavior-macro";
            #binding-cells = <0>;
            bindings =
                <&macro_press>,
                <&kp LALT>,
                <&macro_tap>,
                <&kp KP_NUMBER_0 &kp KP_NUMBER_9 &kp KP_NUMBER_4 &kp KP_NUMBER_5>,
                <&macro_release>,
                <&kp LALT>;

            label = "ALPHA";
        };

        betam: betam {
            compatible = "zmk,behavior-macro";
            #binding-cells = <0>;
            bindings =
                <&macro_press>,
                <&kp LALT>,
                <&macro_tap>,
                <&kp KP_NUMBER_0 &kp KP_NUMBER_9 &kp KP_NUMBER_4 &kp KP_NUMBER_6>,
                <&macro_release>,
                <&kp LALT>;

            label = "BETAM";
        };

        gammam: gammam {
            compatible = "zmk,behavior-macro";
            #binding-cells = <0>;
            bindings =
                <&macro_press>,
                <&kp LALT>,
                <&macro_tap>,
                <&kp KP_NUMBER_0 &kp KP_NUMBER_9 &kp KP_NUMBER_4 &kp KP_NUMBER_7>,
                <&macro_release>,
                <&kp LALT>;

            label = "GAMMAM";
        };

        Delta: Delta {
            compatible = "zmk,behavior-macro";
            #binding-cells = <0>;
            bindings =
                <&macro_press>,
                <&kp LALT>,
                <&macro_tap>,
                <&kp KP_NUMBER_0 &kp KP_NUMBER_9 &kp KP_NUMBER_1 &kp KP_NUMBER_6>,
                <&macro_release>,
                <&kp LALT>;

            label = "DELTA";
        };

        epsilonm: epsilonm {
            compatible = "zmk,behavior-macro";
            #binding-cells = <0>;
            bindings =
                <&macro_press>,
                <&kp LALT>,
                <&macro_tap>,
                <&kp KP_NUMBER_0 &kp KP_NUMBER_9 &kp KP_NUMBER_4 &kp KP_NUMBER_9>,
                <&macro_release>,
                <&kp LALT>;

            label = "EPSILONM";
        };

        zetam: zetam {
            compatible = "zmk,behavior-macro";
            #binding-cells = <0>;
            bindings =
                <&macro_press>,
                <&kp LALT>,
                <&macro_tap>,
                <&kp KP_NUMBER_0 &kp KP_NUMBER_9 &kp KP_NUMBER_5 &kp KP_NUMBER_0>,
                <&macro_release>,
                <&kp LALT>;

            label = "ZETAM";
        };

        thetam: thetam {
            compatible = "zmk,behavior-macro";
            #binding-cells = <0>;
            bindings =
                <&macro_press>,
                <&kp LALT>,
                <&macro_tap>,
                <&kp KP_NUMBER_0 &kp KP_NUMBER_9 &kp KP_NUMBER_5 &kp KP_NUMBER_2>,
                <&macro_release>,
                <&kp LALT>;

            label = "THETAM";
        };

        lambda: lambda {
            compatible = "zmk,behavior-macro";
            #binding-cells = <0>;
            bindings =
                <&macro_press>,
                <&kp LALT>,
                <&macro_tap>,
                <&kp KP_NUMBER_0 &kp KP_NUMBER_9 &kp KP_NUMBER_5 &kp KP_NUMBER_5>,
                <&macro_release>,
                <&kp LALT>;

            label = "LAMBDA";
        };

        mum: mum {
            compatible = "zmk,behavior-macro";
            #binding-cells = <0>;
            bindings =
                <&macro_press>,
                <&kp LALT>,
                <&macro_tap>,
                <&kp KP_NUMBER_0 &kp KP_NUMBER_9 &kp KP_NUMBER_5 &kp KP_NUMBER_6>,
                <&macro_release>,
                <&kp LALT>;

            label = "MUM";
        };

        pim: pim {
            compatible = "zmk,behavior-macro";
            #binding-cells = <0>;
            bindings =
                <&macro_press>,
                <&kp LALT>,
                <&macro_tap>,
                <&kp KP_NUMBER_0 &kp KP_NUMBER_9 &kp KP_NUMBER_6 &kp KP_NUMBER_0>,
                <&macro_release>,
                <&kp LALT>;

            label = "PIM";
        };

        Sigmam: Sigmam {
            compatible = "zmk,behavior-macro";
            #binding-cells = <0>;
            bindings =
                <&macro_press>,
                <&kp LALT>,
                <&macro_tap>,
                <&kp KP_NUMBER_0 &kp KP_NUMBER_9 &kp KP_NUMBER_3 &kp KP_NUMBER_1>,
                <&macro_release>,
                <&kp LALT>;

            label = "SIGMAM";
        };

        phim: phim {
            compatible = "zmk,behavior-macro";
            #binding-cells = <0>;
            bindings =
                <&macro_press>,
                <&kp LALT>,
                <&macro_tap>,
                <&kp KP_NUMBER_0 &kp KP_NUMBER_9 &kp KP_NUMBER_6 &kp KP_NUMBER_6>,
                <&macro_release>,
                <&kp LALT>;

            label = "PHIM";
        };

        psim: psim {
            compatible = "zmk,behavior-macro";
            #binding-cells = <0>;
            bindings =
                <&macro_press>,
                <&kp LALT>,
                <&macro_tap>,
                <&kp KP_NUMBER_0 &kp KP_NUMBER_9 &kp KP_NUMBER_6 &kp KP_NUMBER_8>,
                <&macro_release>,
                <&kp LALT>;

            label = "PSIM";
        };

        omega: omega {
            compatible = "zmk,behavior-macro";
            #binding-cells = <0>;
            bindings =
                <&macro_press>,
                <&kp LALT>,
                <&macro_tap>,
                <&kp KP_NUMBER_0 &kp KP_NUMBER_9 &kp KP_NUMBER_3 &kp KP_NUMBER_7>,
                <&macro_release>,
                <&kp LALT>;

            label = "OMEGA";
        };

        omegam: omegam {
            compatible = "zmk,behavior-macro";
            #binding-cells = <0>;
            bindings =
                <&macro_press>,
                <&kp LALT>,
                <&macro_tap>,
                <&kp KP_NUMBER_0 &kp KP_NUMBER_9 &kp KP_NUMBER_6 &kp KP_NUMBER_9>,
                <&macro_release>,
                <&kp LALT>;

            label = "OMEGAM";
        };

        pound: pound {
            compatible = "zmk,behavior-macro";
            #binding-cells = <0>;
            bindings =
                <&macro_press>,
                <&kp LALT>,
                <&macro_tap>,
                <&kp KP_NUMBER_0 &kp KP_NUMBER_1 &kp KP_NUMBER_6 &kp KP_NUMBER_3>,
                <&macro_release>,
                <&kp LALT>;

            label = "POUND";
        };

        euro: euro {
            compatible = "zmk,behavior-macro";
            #binding-cells = <0>;
            bindings =
                <&macro_press>,
                <&kp LALT>,
                <&macro_tap>,
                <&kp KP_NUMBER_0 &kp KP_NUMBER_1 &kp KP_NUMBER_2 &kp KP_NUMBER_8>,
                <&macro_release>,
                <&kp LALT>;

            label = "EURO";
        };

        currency: currency {
            compatible = "zmk,behavior-macro";
            #binding-cells = <0>;
            bindings =
                <&macro_press>,
                <&kp LALT>,
                <&macro_tap>,
                <&kp KP_NUMBER_0 &kp KP_NUMBER_1 &kp KP_NUMBER_6 &kp KP_NUMBER_4>,
                <&macro_release>,
                <&kp LALT>;

            label = "CURRENCY";
        };

        multi: multi {
            compatible = "zmk,behavior-macro";
            #binding-cells = <0>;
            bindings =
                <&macro_press>,
                <&kp LALT>,
                <&macro_tap>,
                <&kp KP_NUMBER_0 &kp KP_NUMBER_2 &kp KP_NUMBER_1 &kp KP_NUMBER_5>,
                <&macro_release>,
                <&kp LALT>;

            label = "MULTI";
        };

        division: division {
            compatible = "zmk,behavior-macro";
            #binding-cells = <0>;
            bindings =
                <&macro_press>,
                <&kp LALT>,
                <&macro_tap>,
                <&kp KP_NUMBER_0 &kp KP_NUMBER_2 &kp KP_NUMBER_4 &kp KP_NUMBER_7>,
                <&macro_release>,
                <&kp LALT>;

            label = "DIVISION";
        };

        racine: racine {
            compatible = "zmk,behavior-macro";
            #binding-cells = <0>;
            bindings =
                <&macro_press>,
                <&kp LALT>,
                <&macro_tap>,
                <&kp KP_NUMBER_0 &kp KP_NUMBER_2 &kp KP_NUMBER_5 &kp KP_NUMBER_1>,
                <&macro_release>,
                <&kp LALT>;

            label = "RACINE";
        };

        carret: carret {
            compatible = "zmk,behavior-macro";
            #binding-cells = <0>;
            bindings =
                <&macro_press>,
                <&kp LALT>,
                <&macro_tap>,
                <&kp KP_NUMBER_0 &kp KP_NUMBER_1 &kp KP_NUMBER_3 &kp KP_NUMBER_6>,
                <&macro_release>,
                <&kp LALT>;

            label = "CARRET";
        };

        puce: puce {
            compatible = "zmk,behavior-macro";
            #binding-cells = <0>;
            bindings =
                <&macro_press>,
                <&kp LALT>,
                <&macro_tap>,
                <&kp KP_NUMBER_0 &kp KP_NUMBER_1 &kp KP_NUMBER_4 &kp KP_NUMBER_9>,
                <&macro_release>,
                <&kp LALT>;

            label = "PUCE";
        };

        copyright: copyright {
            compatible = "zmk,behavior-macro";
            #binding-cells = <0>;
            bindings =
                <&macro_press>,
                <&kp LALT>,
                <&macro_tap>,
                <&kp KP_NUMBER_0 &kp KP_NUMBER_1 &kp KP_NUMBER_6 &kp KP_NUMBER_9>,
                <&macro_release>,
                <&kp LALT>;

            label = "COPYRIGHT";
        };

        label: label {
            compatible = "zmk,behavior-macro";
            #binding-cells = <0>;
            bindings =
                <&macro_press>,
                <&kp LALT>,
                <&macro_tap>,
                <&kp KP_NUMBER_0 &kp KP_NUMBER_1 &kp KP_NUMBER_7 &kp KP_NUMBER_4>,
                <&macro_release>,
                <&kp LALT>;

            label = "LABEL";
        };

        trademark: trademark {
            compatible = "zmk,behavior-macro";
            #binding-cells = <0>;
            bindings =
                <&macro_press>,
                <&kp LALT>,
                <&macro_tap>,
                <&kp KP_NUMBER_0 &kp KP_NUMBER_1 &kp KP_NUMBER_5 &kp KP_NUMBER_3>,
                <&macro_release>,
                <&kp LALT>;

            label = "TRADEMARK";
        };

        nouv_para: nouv_para {
            compatible = "zmk,behavior-macro";
            #binding-cells = <0>;
            bindings =
                <&macro_press>,
                <&kp LALT>,
                <&macro_tap>,
                <&kp KP_NUMBER_0 &kp KP_NUMBER_1 &kp KP_NUMBER_6 &kp KP_NUMBER_7>,
                <&macro_release>,
                <&kp LALT>;

            label = "NOUV_PARA";
        };

        paragraphe: paragraphe {
            compatible = "zmk,behavior-macro";
            #binding-cells = <0>;
            bindings =
                <&macro_press>,
                <&kp LALT>,
                <&macro_tap>,
                <&kp KP_NUMBER_0 &kp KP_NUMBER_1 &kp KP_NUMBER_8 &kp KP_NUMBER_2>,
                <&macro_release>,
                <&kp LALT>;

            label = "PARAGRAPHE";
        };

        bemol: bemol {
            compatible = "zmk,behavior-macro";
            #binding-cells = <0>;
            bindings =
                <&macro_press>,
                <&kp LALT>,
                <&macro_tap>,
                <&kp KP_NUMBER_9 &kp KP_NUMBER_8 &kp KP_NUMBER_3 &kp KP_NUMBER_7>,
                <&macro_release>,
                <&kp LALT>;

            label = "BEMOL";
        };

        becarre: becarre {
            compatible = "zmk,behavior-macro";
            #binding-cells = <0>;
            bindings =
                <&macro_press>,
                <&kp LALT>,
                <&macro_tap>,
                <&kp KP_NUMBER_9 &kp KP_NUMBER_8 &kp KP_NUMBER_3 &kp KP_NUMBER_8>,
                <&macro_release>,
                <&kp LALT>;

            label = "BECARRE";
        };

        degre: degre {
            compatible = "zmk,behavior-macro";
            #binding-cells = <0>;
            bindings =
                <&macro_press>,
                <&kp LALT>,
                <&macro_tap>,
                <&kp KP_NUMBER_0 &kp KP_NUMBER_1 &kp KP_NUMBER_7 &kp KP_NUMBER_6>,
                <&macro_release>,
                <&kp LALT>;

            label = "DEGRE";
        };

        median: median {
            compatible = "zmk,behavior-macro";
            #binding-cells = <0>;
            bindings =
                <&macro_press>,
                <&kp LALT>,
                <&macro_tap>,
                <&kp KP_NUMBER_0 &kp KP_NUMBER_1 &kp KP_NUMBER_8 &kp KP_NUMBER_3>,
                <&macro_release>,
                <&kp LALT>;

            label = "MEDIAN";
        };

        french_quote_open: french_quote_open {
            compatible = "zmk,behavior-macro";
            #binding-cells = <0>;
            bindings =
                <&macro_press>,
                <&kp LALT>,
                <&macro_tap>,
                <&kp KP_NUMBER_0 &kp KP_NUMBER_1 &kp KP_NUMBER_7 &kp KP_NUMBER_1>,
                <&macro_release>,
                <&kp LALT>;

            label = "FRENCH_QUOTE_OPEN";
        };

        french_quote_close: french_quote_close {
            compatible = "zmk,behavior-macro";
            #binding-cells = <0>;
            bindings =
                <&macro_press>,
                <&kp LALT>,
                <&macro_tap>,
                <&kp KP_NUMBER_0 &kp KP_NUMBER_1 &kp KP_NUMBER_8 &kp KP_NUMBER_7>,
                <&macro_release>,
                <&kp LALT>;

            label = "FRENCH_QUOTE_CLOSE";
        };

        acute_accent: acute_accent {
            compatible = "zmk,behavior-macro";
            #binding-cells = <0>;
            bindings =
                <&macro_press>,
                <&kp LALT>,
                <&macro_tap>,
                <&kp KP_NUMBER_0 &kp KP_NUMBER_1 &kp KP_NUMBER_8 &kp KP_NUMBER_0>,
                <&macro_release>,
                <&kp LALT>;

            label = "ACUTE_ACCENT";
        };

        Diaeresis: Diaeresis {
            compatible = "zmk,behavior-macro";
            #binding-cells = <0>;
            bindings =
                <&macro_press>,
                <&kp LALT>,
                <&macro_tap>,
                <&kp KP_NUMBER_0 &kp KP_NUMBER_1 &kp KP_NUMBER_6 &kp KP_NUMBER_8>,
                <&macro_release>,
                <&kp LALT>;

            label = "DIAERESIS";
        };

        dubamps: dubamps {
            compatible = "zmk,behavior-macro";
            #binding-cells = <0>;
            bindings = <&kp AMPS &kp AMPS>;
            label = "DUBAMPS";
        };

        dubpipes: dubpipes {
            compatible = "zmk,behavior-macro";
            #binding-cells = <0>;
            bindings = <&kp PIPE &kp PIPE>;
            label = "DUBPIPES";
        };

        exp1: exp1 {
            compatible = "zmk,behavior-macro";
            #binding-cells = <0>;
            bindings =
                <&macro_press>,
                <&kp LALT>,
                <&macro_tap>,
                <&kp KP_NUMBER_0 &kp KP_NUMBER_1 &kp KP_NUMBER_8 &kp KP_NUMBER_5>,
                <&macro_release>,
                <&kp LALT>;

            label = "EXP1";
        };

        exp2: exp2 {
            compatible = "zmk,behavior-macro";
            #binding-cells = <0>;
            bindings =
                <&macro_press>,
                <&kp LALT>,
                <&macro_tap>,
                <&kp KP_NUMBER_0 &kp KP_NUMBER_1 &kp KP_NUMBER_7 &kp KP_NUMBER_8>,
                <&macro_release>,
                <&kp LALT>;

            label = "EXP2";
        };

        exp3: exp3 {
            compatible = "zmk,behavior-macro";
            #binding-cells = <0>;
            bindings =
                <&macro_press>,
                <&kp LALT>,
                <&macro_tap>,
                <&kp KP_NUMBER_0 &kp KP_NUMBER_1 &kp KP_NUMBER_7 &kp KP_NUMBER_9>,
                <&macro_release>,
                <&kp LALT>;

            label = "EXP3";
        };

        selall: selall {
            compatible = "zmk,behavior-macro";
            #binding-cells = <0>;
            bindings = <&kp LC(A)>;
            label = "SELALL";
        };

        del_word: del_word {
            compatible = "zmk,behavior-macro";
            #binding-cells = <0>;
            bindings = <&kp LC(DEL)>;
            label = "DEL_WORD";
        };

        bspc_word: bspc_word {
            compatible = "zmk,behavior-macro";
            #binding-cells = <0>;
            bindings = <&kp LC(BSPC)>;
            label = "BSPC_WORD";
        };

        Del_line: Del_line {
            compatible = "zmk,behavior-macro";
            #binding-cells = <0>;
            bindings = <&kp HOME &kp LS(END) &kp BSPC>;
            label = "DEL_LINE";
        };

        perma_del: perma_del {
            compatible = "zmk,behavior-macro";
            #binding-cells = <0>;
            bindings = <&kp LS(DEL)>;
            label = "PERMA_DEL";
        };

        page_home: page_home {
            compatible = "zmk,behavior-macro";
            #binding-cells = <0>;
            bindings = <&kp LC(HOME)>;
            label = "PAGE_HOME";
        };

        page_end: page_end {
            compatible = "zmk,behavior-macro";
            #binding-cells = <0>;
            bindings = <&kp LC(END)>;
            label = "PAGE_END";
        };

        laam: laam {
            compatible = "zmk,behavior-macro";
            #binding-cells = <0>;
            bindings = <&kp LC(LS(U)) &kp N0 &kp N0 &kp E &kp N1 &kp RET>;
            label = "LAAM";
        };

        laa: laa {
            compatible = "zmk,behavior-macro";
            #binding-cells = <0>;
            bindings = <&kp LC(LS(U)) &kp N0 &kp N0 &kp E &kp N1 &kp RET>;
            label = "LAA";
        };

        leam: leam {
            compatible = "zmk,behavior-macro";
            #binding-cells = <0>;
            bindings = <&kp LC(LS(U)) &kp N0 &kp N0 &kp E &kp N9 &kp RET>;
            label = "LEAM";
        };

        lea: lea {
            compatible = "zmk,behavior-macro";
            #binding-cells = <0>;
            bindings = <&kp LC(LS(U)) &kp N0 &kp N0 &kp C &kp N9 &kp RET>;
            label = "LEA";
        };

        liam: liam {
            compatible = "zmk,behavior-macro";
            #binding-cells = <0>;
            bindings = <&kp LC(LS(U)) &kp N0 &kp N0 &kp E &kp D &kp RET>;
            label = "LIAM";
        };

        lia: lia {
            compatible = "zmk,behavior-macro";
            #binding-cells = <0>;
            bindings = <&kp LC(LS(U)) &kp N0 &kp N0 &kp C &kp D &kp RET>;
            label = "LIA";
        };

        loam: loam {
            compatible = "zmk,behavior-macro";
            #binding-cells = <0>;
            bindings = <&kp LC(LS(U)) &kp N0 &kp N0 &kp F &kp N3 &kp RET>;
            label = "LOAM";
        };

        loa: loa {
            compatible = "zmk,behavior-macro";
            #binding-cells = <0>;
            bindings = <&kp LC(LS(U)) &kp N0 &kp N0 &kp D &kp N3 &kp RET>;
            label = "LOA";
        };

        luam: luam {
            compatible = "zmk,behavior-macro";
            #binding-cells = <0>;
            bindings = <&kp LC(LS(U)) &kp N0 &kp N0 &kp F &kp A &kp RET>;
            label = "LUAM";
        };

        lua: lua {
            compatible = "zmk,behavior-macro";
            #binding-cells = <0>;
            bindings = <&kp LC(LS(U)) &kp N0 &kp N0 &kp D &kp A &kp RET>;
            label = "LUA";
        };

        lagm: lagm {
            compatible = "zmk,behavior-macro";
            #binding-cells = <0>;
            bindings = <&kp LC(LS(U)) &kp N0 &kp N0 &kp E &kp N0 &kp RET>;
            label = "LAGM";
        };

        lag: lag {
            compatible = "zmk,behavior-macro";
            #binding-cells = <0>;
            bindings = <&kp LC(LS(U)) &kp N0 &kp N0 &kp C &kp N0 &kp RET>;
            label = "LAG";
        };

        legm: legm {
            compatible = "zmk,behavior-macro";
            #binding-cells = <0>;
            bindings = <&kp LC(LS(U)) &kp N0 &kp N0 &kp E &kp N8 &kp RET>;
            label = "LEGM";
        };

        leg: leg {
            compatible = "zmk,behavior-macro";
            #binding-cells = <0>;
            bindings = <&kp LC(LS(U)) &kp N0 &kp N0 &kp C &kp N8 &kp RET>;
            label = "LEG";
        };

        ligm: ligm {
            compatible = "zmk,behavior-macro";
            #binding-cells = <0>;
            bindings = <&kp LC(LS(U)) &kp N0 &kp N0 &kp E &kp C &kp RET>;
            label = "LIGM";
        };

        lig: lig {
            compatible = "zmk,behavior-macro";
            #binding-cells = <0>;
            bindings = <&kp LC(LS(U)) &kp N0 &kp N0 &kp C &kp C &kp RET>;
            label = "LIG";
        };

        logm: logm {
            compatible = "zmk,behavior-macro";
            #binding-cells = <0>;
            bindings = <&kp LC(LS(U)) &kp N0 &kp N0 &kp F &kp N2 &kp RET>;
            label = "LOGM";
        };

        log: log {
            compatible = "zmk,behavior-macro";
            #binding-cells = <0>;
            bindings = <&kp LC(LS(U)) &kp N0 &kp N0 &kp D &kp N2 &kp RET>;
            label = "LOG";
        };

        lugm: lugm {
            compatible = "zmk,behavior-macro";
            #binding-cells = <0>;
            bindings = <&kp LC(LS(U)) &kp N0 &kp N0 &kp F &kp N9 &kp RET>;
            label = "LUGM";
        };

        lug: lug {
            compatible = "zmk,behavior-macro";
            #binding-cells = <0>;
            bindings = <&kp LC(LS(U)) &kp N0 &kp N0 &kp D &kp N9 &kp RET>;
            label = "LUG";
        };

        ladm: ladm {
            compatible = "zmk,behavior-macro";
            #binding-cells = <0>;
            bindings = <&kp LC(LS(U)) &kp N0 &kp N0 &kp E &kp N4 &kp RET>;
            label = "LADM";
        };

        lad: lad {
            compatible = "zmk,behavior-macro";
            #binding-cells = <0>;
            bindings = <&kp LC(LS(U)) &kp N0 &kp N0 &kp C &kp N4 &kp RET>;
            label = "LAD";
        };

        ledm: ledm {
            compatible = "zmk,behavior-macro";
            #binding-cells = <0>;
            bindings = <&kp LC(LS(U)) &kp N0 &kp N0 &kp E &kp B &kp RET>;
            label = "LEDM";
        };

        led: led {
            compatible = "zmk,behavior-macro";
            #binding-cells = <0>;
            bindings = <&kp LC(LS(U)) &kp N0 &kp N0 &kp C &kp B &kp RET>;
            label = "LED";
        };

        lidm: lidm {
            compatible = "zmk,behavior-macro";
            #binding-cells = <0>;
            bindings = <&kp LC(LS(U)) &kp N0 &kp N0 &kp E &kp F &kp RET>;
            label = "LIDM";
        };

        lid: lid {
            compatible = "zmk,behavior-macro";
            #binding-cells = <0>;
            bindings = <&kp LC(LS(U)) &kp N0 &kp N0 &kp C &kp F &kp RET>;
            label = "LID";
        };

        lodm: lodm {
            compatible = "zmk,behavior-macro";
            #binding-cells = <0>;
            bindings = <&kp LC(LS(U)) &kp N0 &kp N0 &kp F &kp N6 &kp RET>;
            label = "LODM";
        };

        lod: lod {
            compatible = "zmk,behavior-macro";
            #binding-cells = <0>;
            bindings = <&kp LC(LS(U)) &kp N0 &kp N0 &kp D &kp N6 &kp RET>;
            label = "LOD";
        };

        ludm: ludm {
            compatible = "zmk,behavior-macro";
            #binding-cells = <0>;
            bindings = <&kp LC(LS(U)) &kp N0 &kp N0 &kp F &kp C &kp RET>;
            label = "LUDM";
        };

        lud: lud {
            compatible = "zmk,behavior-macro";
            #binding-cells = <0>;
            bindings = <&kp LC(LS(U)) &kp N0 &kp N0 &kp D &kp C &kp RET>;
            label = "LUD";
        };

        lacm: lacm {
            compatible = "zmk,behavior-macro";
            #binding-cells = <0>;
            bindings = <&kp LC(LS(U)) &kp N0 &kp N0 &kp E &kp N2 &kp RET>;
            label = "LACM";
        };

        lac: lac {
            compatible = "zmk,behavior-macro";
            #binding-cells = <0>;
            bindings = <&kp LC(LS(U)) &kp N0 &kp N0 &kp C &kp N2 &kp RET>;
            label = "LAC";
        };

        lecm: lecm {
            compatible = "zmk,behavior-macro";
            #binding-cells = <0>;
            bindings = <&kp LC(LS(U)) &kp N0 &kp N0 &kp E &kp A &kp RET>;
            label = "LECM";
        };

        lec: lec {
            compatible = "zmk,behavior-macro";
            #binding-cells = <0>;
            bindings = <&kp LC(LS(U)) &kp N0 &kp N0 &kp C &kp A &kp RET>;
            label = "LEC";
        };

        licm: licm {
            compatible = "zmk,behavior-macro";
            #binding-cells = <0>;
            bindings = <&kp LC(LS(U)) &kp N0 &kp N0 &kp E &kp E &kp RET>;
            label = "LICM";
        };

        lic: lic {
            compatible = "zmk,behavior-macro";
            #binding-cells = <0>;
            bindings = <&kp LC(LS(U)) &kp N0 &kp N0 &kp C &kp E &kp RET>;
            label = "LIC";
        };

        locm: locm {
            compatible = "zmk,behavior-macro";
            #binding-cells = <0>;
            bindings = <&kp LC(LS(U)) &kp N0 &kp N0 &kp F &kp N4 &kp RET>;
            label = "LOCM";
        };

        loc: loc {
            compatible = "zmk,behavior-macro";
            #binding-cells = <0>;
            bindings = <&kp LC(LS(U)) &kp N0 &kp N0 &kp D &kp N4 &kp RET>;
            label = "LOC";
        };

        lucm: lucm {
            compatible = "zmk,behavior-macro";
            #binding-cells = <0>;
            bindings = <&kp LC(LS(U)) &kp N0 &kp N0 &kp F &kp B &kp RET>;
            label = "LUCM";
        };

        luc: luc {
            compatible = "zmk,behavior-macro";
            #binding-cells = <0>;
            bindings = <&kp LC(LS(U)) &kp N0 &kp N0 &kp D &kp B &kp RET>;
            label = "LUC";
        };

        latm: latm {
            compatible = "zmk,behavior-macro";
            #binding-cells = <0>;
            bindings = <&kp LC(LS(U)) &kp N0 &kp N0 &kp E &kp N3 &kp RET>;
            label = "LATM";
        };

        lat: lat {
            compatible = "zmk,behavior-macro";
            #binding-cells = <0>;
            bindings = <&kp LC(LS(U)) &kp N0 &kp N0 &kp C &kp N3 &kp RET>;
            label = "LAT";
        };

        lotm: lotm {
            compatible = "zmk,behavior-macro";
            #binding-cells = <0>;
            bindings = <&kp LC(LS(U)) &kp N0 &kp N0 &kp F &kp N5 &kp RET>;
            label = "LOTM";
        };

        lot: lot {
            compatible = "zmk,behavior-macro";
            #binding-cells = <0>;
            bindings = <&kp LC(LS(U)) &kp N0 &kp N0 &kp D &kp N5 &kp RET>;
            label = "LOT";
        };

        lntm: lntm {
            compatible = "zmk,behavior-macro";
            #binding-cells = <0>;
            bindings = <&kp LC(LS(U)) &kp N0 &kp N0 &kp F &kp N1 &kp RET>;
            label = "LNTM";
        };

        lnt: lnt {
            compatible = "zmk,behavior-macro";
            #binding-cells = <0>;
            bindings = <&kp LC(LS(U)) &kp N0 &kp N0 &kp D &kp N1 &kp RET>;
            label = "LNT";
        };

        laem: laem {
            compatible = "zmk,behavior-macro";
            #binding-cells = <0>;
            bindings = <&kp LC(LS(U)) &kp N0 &kp N0 &kp E &kp N6 &kp RET>;
            label = "LAEM";
        };

        lae: lae {
            compatible = "zmk,behavior-macro";
            #binding-cells = <0>;
            bindings = <&kp LC(LS(U)) &kp N0 &kp N0 &kp C &kp N6 &kp RET>;
            label = "LAE";
        };

        loem: loem {
            compatible = "zmk,behavior-macro";
            #binding-cells = <0>;
            bindings = <&kp LC(LS(U)) &kp N0 &kp N1 &kp N5 &kp N3 &kp RET>;
            label = "LOEM";
        };

        loe: loe {
            compatible = "zmk,behavior-macro";
            #binding-cells = <0>;
            bindings = <&kp LC(LS(U)) &kp N0 &kp N1 &kp N5 &kp NUMBER_2 &kp RET>;
            label = "LOE";
        };

        lcedillem: lcedillem {
            compatible = "zmk,behavior-macro";
            #binding-cells = <0>;
            bindings = <&kp LC(LS(U)) &kp N0 &kp N0 &kp E &kp N7 &kp RET>;
            label = "LCEDILLEM";
        };

        lcedille: lcedille {
            compatible = "zmk,behavior-macro";
            #binding-cells = <0>;
            bindings = <&kp LC(LS(U)) &kp N0 &kp N0 &kp C &kp N7 &kp RET>;
            label = "LCEDILLE";
        };

        lss: lss {
            compatible = "zmk,behavior-macro";
            #binding-cells = <0>;
            bindings = <&kp LC(LS(U)) &kp N0 &kp N0 &kp D &kp F &kp RET>;
            label = "LSS";
        };

        larm: larm {
            compatible = "zmk,behavior-macro";
            #binding-cells = <0>;
            bindings = <&kp LC(LS(U)) &kp N0 &kp N0 &kp E &kp N5 &kp RET>;
            label = "LARM";
        };

        lar: lar {
            compatible = "zmk,behavior-macro";
            #binding-cells = <0>;
            bindings = <&kp LC(LS(U)) &kp N0 &kp N0 &kp C &kp N5 &kp RET>;
            label = "LAR";
        };

        losm: losm {
            compatible = "zmk,behavior-macro";
            #binding-cells = <0>;
            bindings = <&kp LC(LS(U)) &kp N0 &kp N0 &kp F &kp N8 &kp RET>;
            label = "LOSM";
        };

        los: los {
            compatible = "zmk,behavior-macro";
            #binding-cells = <0>;
            bindings = <&kp LC(LS(U)) &kp N0 &kp N0 &kp D &kp N8 &kp RET>;
            label = "LOS";
        };

        lalpham: lalpham {
            compatible = "zmk,behavior-macro";
            #binding-cells = <0>;
            bindings = <&kp LC(LS(U)) &kp N0 &kp N3 &kp B &kp N1 &kp RET>;
            label = "LALPHAM";
        };

        lbetam: lbetam {
            compatible = "zmk,behavior-macro";
            #binding-cells = <0>;
            bindings = <&kp LC(LS(U)) &kp N0 &kp N3 &kp B &kp NUMBER_2 &kp RET>;
            label = "LBETAM";
        };

        lgammam: lgammam {
            compatible = "zmk,behavior-macro";
            #binding-cells = <0>;
            bindings = <&kp LC(LS(U)) &kp N0 &kp N3 &kp B &kp NUMBER_3 &kp RET>;
            label = "LGAMMAM";
        };

        lepsilonm: lepsilonm {
            compatible = "zmk,behavior-macro";
            #binding-cells = <0>;
            bindings = <&kp LS(LC(U)) &kp N0 &kp N3 &kp B &kp N5 &kp RET>;
            label = "LEPSILONM";
        };

        lzetam: lzetam {
            compatible = "zmk,behavior-macro";
            #binding-cells = <0>;
            bindings = <&kp LS(LC(U)) &kp N0 &kp N3 &kp B &kp NUMBER_6 &kp RET>;
            label = "LZETAM";
        };

        lthetam: lthetam {
            compatible = "zmk,behavior-macro";
            #binding-cells = <0>;
            bindings = <&kp LS(LC(U)) &kp N0 &kp N3 &kp B &kp N8 &kp RET>;
            label = "LTHETAM";
        };

        lmum: lmum {
            compatible = "zmk,behavior-macro";
            #binding-cells = <0>;
            bindings = <&kp LS(LC(U)) &kp N0 &kp N3 &kp B &kp C &kp RET>;
            label = "LMUM";
        };

        lpim: lpim {
            compatible = "zmk,behavior-macro";
            #binding-cells = <0>;
            bindings = <&kp LS(LC(U)) &kp N0 &kp N3 &kp C &kp N0 &kp RET>;
            label = "LPIM";
        };

        lphim: lphim {
            compatible = "zmk,behavior-macro";
            #binding-cells = <0>;
            bindings = <&kp LS(LC(U)) &kp N0 &kp N3 &kp C &kp NUMBER_6 &kp RET>;
            label = "LPHIM";
        };

        lpsim: lpsim {
            compatible = "zmk,behavior-macro";
            #binding-cells = <0>;
            bindings = <&kp LS(LC(U)) &kp N0 &kp N3 &kp C &kp N8 &kp RET>;
            label = "LPSIM";
        };

        lomegam: lomegam {
            compatible = "zmk,behavior-macro";
            #binding-cells = <0>;
            bindings = <&kp LS(LC(U)) &kp N0 &kp N3 &kp C &kp N9 &kp RET>;
            label = "LOMEGAM";
        };

        ldelta: ldelta {
            compatible = "zmk,behavior-macro";
            #binding-cells = <0>;
            bindings = <&kp LS(LC(U)) &kp N0 &kp N3 &kp N9 &kp N4 &kp RET>;
            label = "LDELTA";
        };

        lsigma: lsigma {
            compatible = "zmk,behavior-macro";
            #binding-cells = <0>;
            bindings = <&kp LS(LC(U)) &kp N0 &kp N3 &kp N9 &kp B &kp RET>;
            label = "LSIGMA";
        };

        lomega: lomega {
            compatible = "zmk,behavior-macro";
            #binding-cells = <0>;
            bindings = <&kp LS(LC(U)) &kp N0 &kp N3 &kp A &kp N9 &kp RET>;
            label = "LOMEGA";
        };

        llambdam: llambdam {
            compatible = "zmk,behavior-macro";
            #binding-cells = <0>;
            bindings = <&kp LS(LC(U)) &kp N0 &kp N3 &kp B &kp B &kp RET>;
            label = "LLAMBDAM";
        };

        lpound: lpound {
            compatible = "zmk,behavior-macro";
            #binding-cells = <0>;
            bindings = <&kp LS(LC(U)) &kp N0 &kp N0 &kp A &kp N3 &kp RET>;
            label = "LPOUND";
        };

        leuro: leuro {
            compatible = "zmk,behavior-macro";
            #binding-cells = <0>;
            bindings = <&kp LS(LC(U)) &kp N2 &kp N0 &kp A &kp C &kp RET>;
            label = "LEURO";
        };

        lcurrency: lcurrency {
            compatible = "zmk,behavior-macro";
            #binding-cells = <0>;
            bindings = <&kp LS(LC(U)) &kp N0 &kp N0 &kp A &kp NUMBER_4 &kp RET>;
            label = "LCURRENCY";
        };

        lmulti: lmulti {
            compatible = "zmk,behavior-macro";
            #binding-cells = <0>;
            bindings = <&kp LS(LC(U)) &kp N0 &kp N0 &kp D &kp N7 &kp RET>;
            label = "LMULTI";
        };

        ldiv: ldiv {
            compatible = "zmk,behavior-macro";
            #binding-cells = <0>;
            bindings = <&kp LS(LC(U)) &kp N0 &kp N0 &kp F &kp N7 &kp RET>;
            label = "LDIV";
        };

        lsquareroot: lsquareroot {
            compatible = "zmk,behavior-macro";
            #binding-cells = <0>;
            bindings = <&kp LS(LC(U)) &kp N2 &kp N2 &kp N1 &kp A &kp RET>;
            label = "LSQUAREROOT";
        };

        lcarret: lcarret {
            compatible = "zmk,behavior-macro";
            #binding-cells = <0>;
            bindings = <&kp LS(LC(U)) &kp N0 &kp N0 &kp N5 &kp E &kp RET>;
            label = "LCARRET";
        };

        lpuce: lpuce {
            compatible = "zmk,behavior-macro";
            #binding-cells = <0>;
            bindings = <&kp LS(LC(U)) &kp N2 &kp N0 &kp N2 &kp NUMBER_2 &kp RET>;
            label = "LPUCE";
        };

        lcopyright: lcopyright {
            compatible = "zmk,behavior-macro";
            #binding-cells = <0>;
            bindings = <&kp LS(LC(U)) &kp N0 &kp N0 &kp A &kp N9 &kp RET>;
            label = "LCOPYRIGHT";
        };

        lregistered: lregistered {
            compatible = "zmk,behavior-macro";
            #binding-cells = <0>;
            bindings = <&kp LS(LC(U)) &kp N0 &kp N0 &kp A &kp E &kp RET>;
            label = "LREGISTERED";
        };

        ltm: ltm {
            compatible = "zmk,behavior-macro";
            #binding-cells = <0>;
            bindings = <&kp LS(LC(U)) &kp N2 &kp NUMBER_1 &kp N2 &kp NUMBER_2 &kp RET>;
            label = "LTM";
        };

        lnvpara: lnvpara {
            compatible = "zmk,behavior-macro";
            #binding-cells = <0>;
            bindings = <&kp LS(LC(U)) &kp N0 &kp N0 &kp B &kp N6 &kp RET>;
            label = "LNVPARA";
        };

        lsection: lsection {
            compatible = "zmk,behavior-macro";
            #binding-cells = <0>;
            bindings = <&kp LS(LC(U)) &kp N0 &kp N0 &kp A &kp N7 &kp RET>;
            label = "LSECTION";
        };

        lbecarre: lbecarre {
            compatible = "zmk,behavior-macro";
            #binding-cells = <0>;
            bindings = <&kp LS(LC(U)) &kp N2 &kp N6 &kp N6 &kp E &kp RET>;
            label = "LBECARRE";
        };

        lbemol: lbemol {
            compatible = "zmk,behavior-macro";
            #binding-cells = <0>;
            bindings = <&kp LS(LC(U)) &kp N2 &kp N6 &kp N6 &kp D &kp RET>;
            label = "LBEMOL";
        };

        ldegre: ldegre {
            compatible = "zmk,behavior-macro";
            #binding-cells = <0>;
            bindings = <&kp LS(LC(U)) &kp N0 &kp N0 &kp B &kp N0 &kp RET>;
            label = "LDEGRE";
        };

        lmedian: lmedian {
            compatible = "zmk,behavior-macro";
            #binding-cells = <0>;
            bindings = <&kp LS(LC(U)) &kp N0 &kp N0 &kp B &kp N7 &kp RET>;
            label = "LMEDIAN";
        };

        lfropnquote: lfropnquote {
            compatible = "zmk,behavior-macro";
            #binding-cells = <0>;
            bindings = <&kp LS(LC(U)) &kp N0 &kp N0 &kp A &kp B &kp RET>;
            label = "LFROPNQUOTE";
        };

        lfrclsquote: lfrclsquote {
            compatible = "zmk,behavior-macro";
            #binding-cells = <0>;
            bindings = <&kp LS(LC(U)) &kp N0 &kp N0 &kp B &kp B &kp RET>;
            label = "LFRCLSQUOTE";
        };

        lacute: lacute {
            compatible = "zmk,behavior-macro";
            #binding-cells = <0>;
            bindings = <&kp LS(LC(U)) &kp N0 &kp N0 &kp B &kp NUMBER_4 &kp RET>;
            label = "LACUTE";
        };

        ldiaeresis: ldiaeresis {
            compatible = "zmk,behavior-macro";
            #binding-cells = <0>;
            bindings = <&kp LS(LC(U)) &kp N0 &kp N0 &kp A &kp N8 &kp RET>;
            label = "LDIAERESIS";
        };

        lexp0: lexp0 {
            compatible = "zmk,behavior-macro";
            #binding-cells = <0>;
            bindings = <&kp LS(LC(U)) &kp N2 &kp N0 &kp N7 &kp N0 &kp RET>;
            label = "LEXP0";
        };

        lexp1: lexp1 {
            compatible = "zmk,behavior-macro";
            #binding-cells = <0>;
            bindings = <&kp LS(LC(U)) &kp N0 &kp N0 &kp B &kp N9 &kp RET>;
            label = "LEXP1";
        };

        lexp2: lexp2 {
            compatible = "zmk,behavior-macro";
            #binding-cells = <0>;
            bindings = <&kp LS(LC(U)) &kp N0 &kp N0 &kp B &kp NUMBER_2 &kp RET>;
            label = "LEXP2";
        };

        lexp3: lexp3 {
            compatible = "zmk,behavior-macro";
            #binding-cells = <0>;
            bindings = <&kp LS(LC(U)) &kp N0 &kp N0 &kp B &kp NUMBER_3 &kp RET>;
            label = "LEXP3";
        };

        lexp4: lexp4 {
            compatible = "zmk,behavior-macro";
            #binding-cells = <0>;
            bindings = <&kp LS(LC(U)) &kp N2 &kp N0 &kp N7 &kp NUMBER_4 &kp RET>;
            label = "LEXP4";
        };

        lexp5: lexp5 {
            compatible = "zmk,behavior-macro";
            #binding-cells = <0>;
            bindings = <&kp LS(LC(U)) &kp N2 &kp N0 &kp N7 &kp N5 &kp RET>;
            label = "LEXP5";
        };

        lexp6: lexp6 {
            compatible = "zmk,behavior-macro";
            #binding-cells = <0>;
            bindings = <&kp LS(LC(U)) &kp N2 &kp N0 &kp N7 &kp NUMBER_6 &kp RET>;
            label = "LEXP6";
        };

        lexp7: lexp7 {
            compatible = "zmk,behavior-macro";
            #binding-cells = <0>;
            bindings = <&kp LS(LC(U)) &kp N2 &kp N0 &kp N7 &kp N7 &kp RET>;
            label = "LEXP7";
        };

        lexp8: lexp8 {
            compatible = "zmk,behavior-macro";
            #binding-cells = <0>;
            bindings = <&kp LS(LC(U)) &kp N2 &kp N0 &kp N7 &kp N8 &kp RET>;
            label = "LEXP8";
        };

        lexp9: lexp9 {
            compatible = "zmk,behavior-macro";
            #binding-cells = <0>;
            bindings = <&kp LS(LC(U)) &kp N2 &kp N0 &kp N7 &kp N9 &kp RET>;
            label = "LEXP9";
        };

        llessequal: llessequal {
            compatible = "zmk,behavior-macro";
            #binding-cells = <0>;
            bindings = <&kp LS(LC(U)) &kp N2 &kp NUMBER_2 &kp NUMBER_6 &kp NUMBER_4 &kp RET>;
            label = "LLESSEQUAL";
        };

        lgreaterequal: lgreaterequal {
            compatible = "zmk,behavior-macro";
            #binding-cells = <0>;
            bindings = <&kp LS(LC(U)) &kp N2 &kp NUMBER_2 &kp NUMBER_6 &kp N5 &kp RET>;
            label = "LGREATEREQUAL";
        };

        linequal: linequal {
            compatible = "zmk,behavior-macro";
            #binding-cells = <0>;
            bindings = <&kp LS(LC(U)) &kp N2 &kp NUMBER_2 &kp NUMBER_6 &kp N0 &kp RET>;
            label = "LINEQUAL";
        };

        next_word: next_word {
            compatible = "zmk,behavior-macro";
            #binding-cells = <0>;
            bindings = <&kp LC(RIGHT)>;
            label = "NEXT_WORD";
        };

        prev_word: prev_word {
            compatible = "zmk,behavior-macro";
            #binding-cells = <0>;
            bindings = <&kp LC(LEFT)>;
            label = "PREV_WORD";
        };

        Application_browser: Application_browser {
            compatible = "zmk,behavior-macro";
            #binding-cells = <0>;
            bindings = <&kp LG(A)>;
            label = "APPLICATION_BROWSER";
        };

        winmax: winmax {
            compatible = "zmk,behavior-macro";
            #binding-cells = <0>;
            bindings = <&kp LG(UP)>;
            label = "WINMAX";
        };

        winmin: winmin {
            compatible = "zmk,behavior-macro";
            #binding-cells = <0>;
            bindings = <&kp LG(DOWN)>;
            label = "WINMIN";
        };

        allwinmin: allwinmin {
            compatible = "zmk,behavior-macro";
            #binding-cells = <0>;
            bindings = <&kp LG(D)>;
            label = "ALLWINMIN";
        };

        winright: winright {
            compatible = "zmk,behavior-macro";
            #binding-cells = <0>;
            bindings = <&kp LG(RIGHT)>;
            label = "WINRIGHT";
        };

        winleft: winleft {
            compatible = "zmk,behavior-macro";
            #binding-cells = <0>;
            bindings = <&kp LG(LEFT)>;
            label = "WINLEFT";
        };

        layer_kc: layer_kc {
            compatible = "zmk,behavior-macro";
            #binding-cells = <0>;
            bindings =
                <&macro_press>,
                <&mo 18>,
                <&macro_tap>,
                <&rgb_ug RGB_COLOR_HSB(342,100,70)>,
                <&macro_pause_for_release>,
                <&macro_release>,
                <&mo 18>,
                <&macro_tap>,
                <&rgb_ug RGB_EFR>;

            label = "LAYER_KC";
        };

        layer_cc: layer_cc {
            compatible = "zmk,behavior-macro";
            #binding-cells = <0>;
            bindings =
                <&macro_press>,
                <&mo 0>,
                <&macro_tap>,
                <&rgb_ug RGB_COLOR_HSB(218,87,76)>,
                <&macro_pause_for_release>,
                <&macro_release>,
                <&mo 0>,
                <&macro_tap>,
                <&rgb_ug RGB_EFR>;

            label = "LAYER_CC";
        };

        layer_mediadisp: layer_mediadisp {
            compatible = "zmk,behavior-macro";
            #binding-cells = <0>;
            bindings =
                <&macro_press>,
                <&mo 16>,
                <&macro_tap>,
                <&rgb_ug RGB_COLOR_HSB(132,87,76)>,
                <&macro_pause_for_release>,
                <&macro_release>,
                <&mo 16>,
                <&macro_tap>,
                <&rgb_ug RGB_EFR>;

            label = "LAYER_MEDIADISP";
        };

        layer_applauch: layer_applauch {
            compatible = "zmk,behavior-macro";
            #binding-cells = <0>;
            bindings =
                <&macro_press>,
                <&mo 15>,
                <&macro_tap>,
                <&rgb_ug RGB_COLOR_HSB(171,87,76)>,
                <&macro_pause_for_release>,
                <&macro_release>,
                <&mo 15>,
                <&macro_tap>,
                <&rgb_ug RGB_EFR>;

            label = "LAYER_APPLAUCH";
        };

        layer_windowman: layer_windowman {
            compatible = "zmk,behavior-macro";
            #binding-cells = <0>;
            bindings =
                <&macro_press>,
                <&mo 17>,
                <&macro_tap>,
                <&rgb_ug RGB_COLOR_HSB(65,87,76)>,
                <&macro_pause_for_release>,
                <&macro_release>,
                <&mo 17>,
                <&macro_tap>,
                <&rgb_ug RGB_EFR>;

            label = "LAYER_WINDOWMAN";
        };

        tog_green: tog_green {
            compatible = "zmk,behavior-macro-one-param";
            #binding-cells = <1>;
            bindings =
                <&macro_tap>,
                <&rgb_ug RGB_COLOR_HSB(128,100,49) &macro_param_1to1>,
                <&macro_tap>,
                <&tog MACRO_PLACEHOLDER>;

            label = "TOG_GREEN";
        };
    };

    combos {
        compatible = "zmk,combos";

        gaming_release {
            bindings = <&release_tog 13>;
            key-positions = <38 12 4>;
            layers = <13>;
            timeout-ms = <200>;
        };

        soft_off {
            bindings = <&soft_off>;
            key-positions = <24 35>;
            timeout-ms = <500>;
        };

        applaunch {
            bindings = <&layer_applauch>;
            key-positions = <25 28 35>;
            timeout-ms = <200>;
        };

        mediadisp {
            bindings = <&layer_mediadisp>;
            key-positions = <28 27 35>;
            timeout-ms = <200>;
        };

        windowman {
            bindings = <&layer_windowman>;
            key-positions = <28 26 35>;
            timeout-ms = <200>;
        };

        tog_green {
            bindings = <&tog_green 12>;
            key-positions = <25 39 35>;
        };
    };
};

/ {
    behaviors {
    };

    keymap {
        compatible = "zmk,keymap";

        lin_base {
            bindings = <
&kp ESC   &kp Q  &kp W             &kp F                 &kp P                &kp SEMICOLON    &kp SQT          &kp J           &kp L             &kp U  &kp Y  &lrpar
&kp TAB   &kp A  &homerow LCTRL R  &homerow LEFT_GUI S   &homerow LEFT_ALT T  &kp G            &kp M            &kp N           &kp E             &kp I  &kp O  &lrbkt
&exction  &kp Z  &kp X             &kp C                 &kp V                &kp MINUS        &slbsl           &kp B           &kp D             &kp K  &kp H  &lrbrc
                                   &htkp LSHFT CAPSLOCK  &wgnavi 11 0         &linnumdance     &mo_kp 10 ENTER  &mo_kp 3 SPACE  &orangelayer 1 0
            >;
        };

        lin_lingi_1 {
            bindings = <
&none  &Linux_Acute_A      &Linux_Acute_E      &Linux_Acute_I      &Linux_Acute_O      &Linux_Acute_U        &Linux_Caret_A  &Linux_Caret_E        &Linux_Caret_I   &Linux_Caret_O   &Linux_Caret_U   &none
&none  &Linux_Grave_A      &Linux_Grave_E      &Linux_Grave_I      &Linux_Grave_O      &Linux_Grave_U        &none           &Linux_Tilde_A        &Linux_Tilde_O   &Linux_Tilde_N   &none            &none
&none  &Linux_Diaeresis_A  &Linux_Diaeresis_E  &Linux_Diaeresis_I  &Linux_Diaeresis_O  &Linux_Diaeresis_U    &lss            &Linux_Combo_Cedille  &Linux_Combo_AE  &Linux_Combo_OE  &Linux_Combo_OS  &Linux_Combo_AR
                                               &none               &kp LSHIFT          &Orange_layer_2 2     &none           &none                 &none
            >;
        };

        lin_lingi_2 {
            bindings = <
&none  &none  &none  &none  &none  &none    &lalpham  &lbetam   &lgammam   &ldelta   &lepsilonm  &none
&none  &none  &none  &none  &none  &none    &lzetam   &lthetam  &llambdam  &lmum     &lpim       &none
&none  &none  &none  &none  &none  &none    &lsigma   &lphim    &lpsim     &lomegam  &lomega     &none
                     &none  &none  &none    &trans    &none     &none
            >;
        };

        lin_Symbols {
            bindings = <
&none  &kp INT_YEN  &lpound       &leuro        &kp DOLLAR  &lcurrency    &lbecarre  &lbemol   &kp HASH      &ldegre       &none      &lacute
&none  &lmulti      &ldiv         &lsquareroot  &kp CARET   &lpuce        &kp TILDE  &kp AMPS  &dubamps      &kp PIPE      &dubpipes  &kp GRAVE
&none  &lcopyright  &lregistered  &ltm          &lnvpara    &lsection     &lmedian   &kp AT    &lfropnquote  &lfrclsquote  &none      &ldiaeresis
                                  &none         &none       &none         &none      &none     &none
            >;
        };

        lin_Numeric {
            bindings = <
&kp LGUI   &kp F1  &kp F2   &kp F3   &kp F4   &none             &Linux_Combo_0exp0       &Linux_Combo_1exp1  &Linux_Combo_2exp2  &Linux_Combo_3exp3  &kp PLUS     &kp MINUS
&kp LALT   &kp F5  &kp F6   &kp F7   &kp F8   &none             &Linux_Combo_lesslesseq  &Linux_Combo_4exp4  &Linux_Combo_5exp5  &Linux_Combo_6exp6  &kp ASTRK    &kp FSLH
&kp LCTRL  &kp F9  &kp F10  &kp F11  &kp F12  &kp KP_NUMLOCK    &Linux_Combo_grgrequal   &Linux_Combo_7exp7  &Linux_Combo_8exp8  &Linux_Combo_9exp9  &kp PERCENT  &mo 10
                            &none    &mo 10   &release_tog 4    &kp LSHFT                &Linux_Combo_eine   &kp SPACE
            >;
        };

        win_base {
            bindings = <
&kp ESC   &kp Q  &kp W             &kp F                 &kp P                &kp SEMICOLON    &kp SQT          &kp J           &kp L             &kp U  &kp Y  &lrpar
&kp TAB   &kp A  &homerow LCTRL R  &homerow LEFT_GUI S   &homerow LEFT_ALT T  &kp G            &kp M            &kp N           &kp E             &kp I  &kp O  &lrbkt
&exction  &kp Z  &kp X             &kp C                 &kp V                &kp MINUS        &slbsl           &kp B           &kp D             &kp K  &kp H  &lrbrc
                                   &htkp LSHFT CAPSLOCK  &lgnavi 11 0         &winnumdance     &mo_kp 10 ENTER  &mo_kp 8 SPACE  &orangelayer 6 0
            >;
        };

        win_Lingi_1 {
            bindings = <
&none  &Acute_a      &Acute_e      &Acute_i      &Acute_o      &Acute_u             &Caret_a     &Caret_e   &Caret_i   &Caret_o        &Caret_u         &none
&none  &Grave_a      &Grave_e      &Acute_i      &Grave_o      &Grave_u             &ss          &Tilde_a   &Tilde_o   &Tilde_n        &trans           &none
&none  &Diaeresis_a  &Diaeresis_e  &Diaeresis_i  &Diaeresis_o  &Diaeresis_u         &c_cedille_  &Combi_ae  &Combi_oe  &Combi_o_barre  &Combi_ringed_A  &none
                                   &none         &kp LSHFT     &Orange_layer_2 7    &none        &none      &none
            >;
        };

        win_Lingi_2 {
            bindings = <
&none  &none  &none  &none  &none  &none    &alpham  &betam   &gammam  &Delta  &epsilonm  &none
&none  &none  &none  &none  &none  &none    &zetam   &thetam  &lambda  &mum    &pim       &none
&none  &none  &none  &none  &none  &none    &Sigmam  &phim    &psim    &omega  &omegam    &none
                     &none  &none  &none    &none    &none    &none
            >;
        };

        win_Symbols {
            bindings = <
&none  &kp INT_YEN  &pound     &euro       &kp DOLLAR  &currency      &becarre   &bemol    &kp HASH            &degre               &none      &acute_accent
&none  &multi       &division  &racine     &kp CARET   &puce          &kp TILDE  &kp AMPS  &dubamps            &kp PIPE             &dubpipes  &kp GRAVE
&none  &copyright   &label     &trademark  &nouv_para  &paragraphe    &median    &kp AT    &french_quote_open  &french_quote_close  &none      &Diaeresis
                               &none       &none       &none          &none      &none     &none
            >;
        };

        win_Numeric {
            bindings = <
&kp LGUI   &kp F1  &kp F2   &kp F3   &kp F4   &none             &kp KP_NUMBER_0   &Combi_1_exp1  &Combi_2_exp2  &combi_3_exp3  &kp PLUS     &kp MINUS
&kp LALT   &kp F5  &kp F6   &kp F7   &kp F8   &none             &kp LESS_THAN     &kp KP_N4      &kp KP_N5      &kp KP_N6      &kp ASTRK    &kp FSLH
&kp LCTRL  &kp F9  &kp F10  &kp F11  &kp F12  &kp KP_NUMLOCK    &kp GREATER_THAN  &kp KP_N7      &kp KP_N8      &kp KP_N9      &kp PERCENT  &mo 10
                            &none    &mo 10   &release_tog 9    &kp LSHFT         &kp KP_EQUAL   &kp SPACE
            >;
        };

        Edition {
            bindings = <
&kp TAB        &kp K_UNDO  &prev_word  &kp UP        &next_word     &kp K_REDO    &none  &none            &none       &Del_line    &perma_del  &tog 12
&kp C_AC_SAVE  &kp HOME    &kp LEFT    &kp DOWN      &kp RIGHT      &kp END       &none  &kp BSPC         &bspc_word  &kp DEL      &del_word   &none
&none          &page_home  &kp PG_UP   &selall       &kp PAGE_DOWN  &page_end     &none  &kp K_CUT        &kp K_COPY  &kp K_PASTE  &kp INS     &none
                                       &kp LEFT_ALT  &kp LCTRL      &kp LSHFT     &none  &release_tog 10  &none
            >;
        };

        navi {
            bindings = <
&none  &none      &none      &none     &none     &none    &none     &kp PG_UP  &kp UP    &kp PAGE_DOWN  &none    &none
&none  &kp LSHFT  &kp LCTRL  &kp LGUI  &kp LALT  &none    &kp HOME  &kp LEFT   &kp DOWN  &kp RIGHT      &kp END  &none
&none  &none      &none      &none     &none     &none    &none     &none      &none     &none          &none    &none
                             &none     &none     &none    &none     &none      &none
            >;
        };

        reader_mode {
            bindings = <
&trans  &trans  &trans  &trans  &trans  &trans    &trans   &trans          &kp UP_ARROW    &trans           &trans  &trans
&trans  &trans  &trans  &trans  &trans  &trans    &kp E    &kp LEFT_ARROW  &kp DOWN_ARROW  &kp RIGHT_ARROW  &kp A   &trans
&trans  &trans  &trans  &trans  &trans  &trans    &trans   &kp PAGE_UP     &trans          &kp PAGE_DOWN    &trans  &trans
                        &trans  &trans  &trans    &tog 12  &kp F11         &trans
            >;
        };

        Gaming {
            bindings = <
&kp ESC  &kp T         &kp Q  &kp W   &kp E      &kp R        &none  &none  &none  &none  &none  &none
&kp TAB  &htkp LALT I  &kp A  &kp S   &kp D      &kp F        &none  &none  &none  &none  &none  &none
&kp O    &kp LSHFT     &kp Z  &kp X   &kp C      &kp V        &none  &none  &none  &none  &none  &none
                              &mo 14  &kp LCTRL  &kp SPACE    &none  &none  &none
            >;
        };

        Gaming_num {
            bindings = <
&kp F1  &kp N1  &kp N2  &kp N3  &kp N4  &kp N5     &none  &none  &none  &none  &none  &none
&kp F2  &kp N6  &kp N7  &kp N8  &kp N9  &kp N0     &none  &none  &none  &none  &none  &none
&kp F3  &kp F4  &kp F5  &kp F6  &kp F7  &kp F8     &none  &none  &none  &none  &none  &none
                        &none   &kp F9  &kp F11    &none  &none  &none
            >;
        };

        Applaunch {
            bindings = <
&none  &none  &none  &none  &none  &none    &kp C_AL_MOVIES       &kp C_AL_AUDIO            &kp C_AL_IMAGES         &kp C_AL_CAL  &kp C_AL_MAIL             &none
&none  &none  &none  &none  &none  &none    &kp C_AL_MY_COMPUTER  &kp C_AL_TEXT_EDITOR      &kp C_AL_FILES          &kp C_AL_WWW  &none                     &none
&none  &none  &none  &none  &none  &none    &kp C_AL_CALC         &kp C_AL_GRAPHICS_EDITOR  &kp C_AL_CONTROL_PANEL  &kp C_AL_DB   &kp C_AL_KEYBOARD_LAYOUT  &none
                     &none  &none  &none    &Application_browser  &none                     &none
            >;
        };

        media_display {
            bindings = <
&none  &none          &none         &none         &none          &none             &none  &kp C_VOL_DN      &kp C_VOLUME_UP    &kp C_MUTE  &none  &none
&none  &kp C_BRI_MIN  &kp C_BRI_DN  &kp C_BRI_UP  &kp C_BRI_MAX  &kp C_BRI_AUTO    &none  &kp C_PLAY_PAUSE  &kp C_PREV         &kp C_NEXT  &none  &none
&none  &none          &none         &none         &none          &none             &none  &kp C_REPEAT      &kp C_RANDOM_PLAY  &kp C_STOP  &none  &none
                                    &none         &none          &none             &none  &none             &none
            >;
        };

        window_manager {
            bindings = <
&none  &none  &none  &none  &none  &none    &none  &kp C_AL_PREV_TASK  &winmax     &kp C_AL_NEXT_TASK  &none  &none
&none  &none  &none  &none  &none  &none    &none  &winleft            &winmin     &winright           &none  &none
&none  &none  &none  &none  &none  &none    &none  &none               &allwinmin  &none               &none  &none
                     &none  &none  &none    &none  &none               &none
            >;
        };

        Keyboard_Control {
            bindings = <
&none  &bt BT_SEL 0    &bt BT_SEL 1   &bt BT_SEL 2   &bt BT_SEL 3   &bt BT_SEL 4     &none  &rgb_ug RGB_HUD  &rgb_ug RGB_SAD  &rgb_ug RGB_SAI  &rgb_ug RGB_HUI  &none
&none  &bt BT_CLR_ALL  &bt BT_CLR     &none          &bt BT_PRV     &bt BT_NXT       &none  &rgb_ug RGB_TOG  &rgb_ug RGB_BRD  &rgb_ug RGB_BRI  &none            &none
&none  &bt BT_DISC 0   &bt BT_DISC 1  &bt BT_DISC 2  &bt BT_DISC 3  &bt BT_DISC 4    &none  &rgb_ug RGB_SPD  &rgb_ug RGB_EFR  &rgb_ug RGB_EFF  &rgb_ug RGB_SPI  &none
                                      &none          &none          &none            &none  &none            &none
            >;
        };

        kitty {
            bindings = <
&trans  &kp LC(LS(T))      &kp LC(LS(Q))  &kp LC(LS(LEFT))          &kp LC(LS(RIGHT))          &kp LC(LS(DEL))    &trans  &trans  &trans  &trans  &trans  &trans
&trans  &kp LC(LS(ENTER))  &kp LC(LS(W))  &kp LC(LS(LEFT_BRACKET))  &kp LC(LS(RIGHT_BRACKET))  &trans             &trans  &trans  &trans  &trans  &trans  &trans
&trans  &kp LC(LS(F))      &kp LC(LS(B))  &trans                    &trans                     &trans             &trans  &trans  &trans  &trans  &trans  &trans
                                          &trans                    &trans                     &trans             &trans  &trans  &trans
            >;
        };
    };
};
